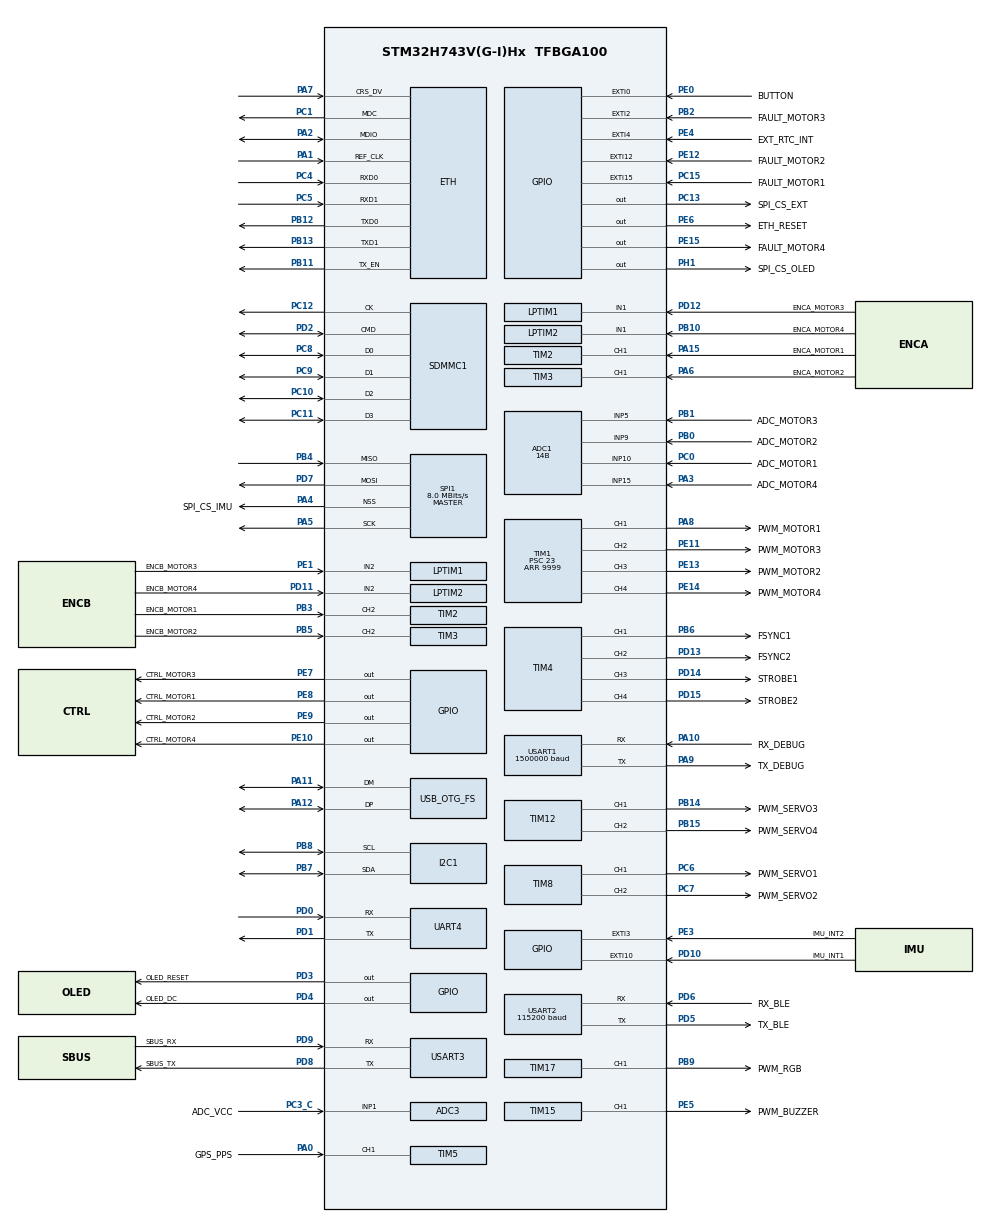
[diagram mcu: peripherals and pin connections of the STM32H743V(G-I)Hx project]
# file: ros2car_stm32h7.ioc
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ADC1.Channel-0\#ChannelRegularConversion=ADC_CHANNEL_10
ADC1.Channel-1\#ChannelRegularConversion=ADC_CHANNEL_9
ADC1.Channel-2\#ChannelRegularConversion=ADC_CHANNEL_5
ADC1.Channel-3\#ChannelRegularConversion=ADC_CHANNEL_15
ADC1.ClockPrescaler=ADC_CLOCK_ASYNC_DIV1
ADC1.ClockPrescalerADC3=ADC_CLOCK_ASYNC_DIV1
ADC1.ContinuousConvMode=ENABLE
ADC1.ConversionDataManagement=ADC_CONVERSIONDATA_DMA_CIRCULAR
ADC1.EOCSelection=ADC_EOC_SEQ_CONV
ADC1.ExternalTrigConv=ADC_SOFTWARE_START
ADC1.NbrOfConversion=4
ADC1.NbrOfConversionFlag=1
ADC1.OffsetNumber-0\#ChannelRegularConversion=ADC_OFFSET_NONE
ADC1.OffsetNumber-1\#ChannelRegularConversion=ADC_OFFSET_NONE
ADC1.OffsetNumber-2\#ChannelRegularConversion=ADC_OFFSET_NONE
ADC1.OffsetNumber-3\#ChannelRegularConversion=ADC_OFFSET_NONE
ADC1.OffsetSignedSaturation-0\#ChannelRegularConversion=DISABLE
ADC1.OffsetSignedSaturation-1\#ChannelRegularConversion=DISABLE
ADC1.OffsetSignedSaturation-2\#ChannelRegularConversion=DISABLE
ADC1.OffsetSignedSaturation-3\#ChannelRegularConversion=DISABLE
ADC1.Overrun=ADC_OVR_DATA_OVERWRITTEN
ADC1.OversamplingMode=ENABLE
ADC1.Rank-0\#ChannelRegularConversion=1
ADC1.Rank-1\#ChannelRegularConversion=2
ADC1.Rank-2\#ChannelRegularConversion=3
ADC1.Rank-3\#ChannelRegularConversion=4
ADC1.Ratio=256
ADC1.Resolution=ADC_RESOLUTION_14B
ADC1.RightBitShift=ADC_RIGHTBITSHIFT_8
ADC1.SamplingTime-0\#ChannelRegularConversion=ADC_SAMPLETIME_64CYCLES_5
ADC1.SamplingTime-1\#ChannelRegularConversion=ADC_SAMPLETIME_64CYCLES_5
ADC1.SamplingTime-2\#ChannelRegularConversion=ADC_SAMPLETIME_64CYCLES_5
ADC1.SamplingTime-3\#ChannelRegularConversion=ADC_SAMPLETIME_64CYCLES_5
ADC1.master=1
ADC3.Channel-0\#ChannelRegularConversion=ADC_CHANNEL_1
ADC3.ClockPrescaler=ADC_CLOCK_ASYNC_DIV1
ADC3.ClockPrescalerADC3=ADC_CLOCK_ASYNC_DIV1
ADC3.ContinuousConvMode=ENABLE
ADC3.ConversionDataManagement=ADC_CONVERSIONDATA_DMA_CIRCULAR
ADC3.ExternalTrigConv=ADC_SOFTWARE_START
ADC3.NbrOfConversionFlag=1
ADC3.OffsetNumber-0\#ChannelRegularConversion=ADC_OFFSET_NONE
ADC3.OffsetSignedSaturation-0\#ChannelRegularConversion=DISABLE
ADC3.Overrun=ADC_OVR_DATA_OVERWRITTEN
ADC3.OversamplingMode=ENABLE
ADC3.Rank-0\#ChannelRegularConversion=1
ADC3.Ratio=1024
ADC3.RightBitShift=ADC_RIGHTBITSHIFT_10
ADC3.SamplingTime-0\#ChannelRegularConversion=ADC_SAMPLETIME_64CYCLES_5
CORTEX_M7.AccessPermission_S-Cortex_Memory_Protection_Unit_Region1_Settings_S=MPU_REGION_FULL_ACCESS
CORTEX_M7.AccessPermission_S-Cortex_Memory_Protection_Unit_Region2_Settings_S=MPU_REGION_FULL_ACCESS
CORTEX_M7.BaseAddress_S-Cortex_Memory_Protection_Unit_Region1_Settings_S=0x30020000
CORTEX_M7.BaseAddress_S-Cortex_Memory_Protection_Unit_Region2_Settings_S=0x30000000
CORTEX_M7.CPU_DCache=Enabled
CORTEX_M7.CPU_ICache=Enabled
CORTEX_M7.DisableExec_S-Cortex_Memory_Protection_Unit_Region2_Settings_S=MPU_INSTRUCTION_ACCESS_DISABLE
CORTEX_M7.Enable_S-Cortex_Memory_Protection_Unit_Region1_Settings_S=MPU_REGION_ENABLE
CORTEX_M7.Enable_S-Cortex_Memory_Protection_Unit_Region2_Settings_S=MPU_REGION_ENABLE
CORTEX_M7.IsBufferable_S-Cortex_Memory_Protection_Unit_Region1_Settings_S=MPU_ACCESS_BUFFERABLE
CORTEX_M7.Size_S-Cortex_Memory_Protection_Unit_Region1_Settings_S=MPU_REGION_SIZE_512B
CORTEX_M7.Size_S-Cortex_Memory_Protection_Unit_Region2_Settings_S=MPU_REGION_SIZE_128KB
CORTEX_M7.TypeExtField_S-Cortex_Memory_Protection_Unit_Region2_Settings_S=MPU_TEX_LEVEL1
CORTEX_M7.default_mode_Activation=1
Dma.ADC1.10.Direction=DMA_PERIPH_TO_MEMORY
Dma.ADC1.10.EventEnable=DISABLE
Dma.ADC1.10.FIFOMode=DMA_FIFOMODE_DISABLE
Dma.ADC1.10.Instance=DMA2_Stream2
Dma.ADC1.10.MemDataAlignment=DMA_MDATAALIGN_HALFWORD
Dma.ADC1.10.MemInc=DMA_MINC_ENABLE
Dma.ADC1.10.Mode=DMA_CIRCULAR
Dma.ADC1.10.PeriphDataAlignment=DMA_PDATAALIGN_HALFWORD
Dma.ADC1.10.PeriphInc=DMA_PINC_DISABLE
Dma.ADC1.10.Polarity=HAL_DMAMUX_REQ_GEN_RISING
Dma.ADC1.10.Priority=DMA_PRIORITY_LOW
Dma.ADC1.10.RequestNumber=1
Dma.ADC1.10.SignalID=NONE
Dma.ADC1.10.SyncEnable=DISABLE
Dma.ADC1.10.SyncPolarity=HAL_DMAMUX_SYNC_NO_EVENT
Dma.ADC1.10.SyncRequestNumber=1
Dma.ADC1.10.SyncSignalID=NONE
Dma.ADC3.11.Direction=DMA_PERIPH_TO_MEMORY
Dma.ADC3.11.EventEnable=DISABLE
Dma.ADC3.11.FIFOMode=DMA_FIFOMODE_ENABLE
Dma.ADC3.11.FIFOThreshold=DMA_FIFO_THRESHOLD_FULL
Dma.ADC3.11.Instance=DMA2_Stream3
Dma.ADC3.11.MemBurst=DMA_MBURST_SINGLE
Dma.ADC3.11.MemDataAlignment=DMA_MDATAALIGN_HALFWORD
Dma.ADC3.11.MemInc=DMA_MINC_ENABLE
Dma.ADC3.11.Mode=DMA_CIRCULAR
Dma.ADC3.11.PeriphBurst=DMA_PBURST_SINGLE
Dma.ADC3.11.PeriphDataAlignment=DMA_PDATAALIGN_HALFWORD
Dma.ADC3.11.PeriphInc=DMA_PINC_DISABLE
Dma.ADC3.11.Polarity=HAL_DMAMUX_REQ_GEN_RISING
Dma.ADC3.11.Priority=DMA_PRIORITY_LOW
Dma.ADC3.11.RequestNumber=1
Dma.ADC3.11.SignalID=NONE
Dma.ADC3.11.SyncEnable=DISABLE
Dma.ADC3.11.SyncPolarity=HAL_DMAMUX_SYNC_NO_EVENT
Dma.ADC3.11.SyncRequestNumber=1
Dma.ADC3.11.SyncSignalID=NONE
Dma.Request0=USART1_RX
Dma.Request1=USART1_TX
Dma.Request10=ADC1
Dma.Request11=ADC3
Dma.Request12=TIM17_CH1
Dma.Request2=USART2_RX
Dma.Request3=USART2_TX
Dma.Request4=USART3_RX
Dma.Request5=USART3_TX
Dma.Request6=UART4_RX
Dma.Request7=UART4_TX
Dma.Request8=SPI1_RX
Dma.Request9=SPI1_TX
Dma.SPI1_RX.8.Direction=DMA_PERIPH_TO_MEMORY
Dma.SPI1_RX.8.EventEnable=DISABLE
Dma.SPI1_RX.8.FIFOMode=DMA_FIFOMODE_DISABLE
Dma.SPI1_RX.8.Instance=DMA2_Stream0
Dma.SPI1_RX.8.MemDataAlignment=DMA_MDATAALIGN_BYTE
Dma.SPI1_RX.8.MemInc=DMA_MINC_ENABLE
Dma.SPI1_RX.8.Mode=DMA_NORMAL
Dma.SPI1_RX.8.PeriphDataAlignment=DMA_PDATAALIGN_BYTE
Dma.SPI1_RX.8.PeriphInc=DMA_PINC_DISABLE
Dma.SPI1_RX.8.Polarity=HAL_DMAMUX_REQ_GEN_RISING
Dma.SPI1_RX.8.Priority=DMA_PRIORITY_LOW
Dma.SPI1_RX.8.RequestNumber=1
Dma.SPI1_RX.8.SignalID=NONE
Dma.SPI1_RX.8.SyncEnable=DISABLE
Dma.SPI1_RX.8.SyncPolarity=HAL_DMAMUX_SYNC_NO_EVENT
Dma.SPI1_RX.8.SyncRequestNumber=1
Dma.SPI1_RX.8.SyncSignalID=NONE
Dma.SPI1_TX.9.Direction=DMA_MEMORY_TO_PERIPH
Dma.SPI1_TX.9.EventEnable=DISABLE
Dma.SPI1_TX.9.FIFOMode=DMA_FIFOMODE_DISABLE
Dma.SPI1_TX.9.Instance=DMA2_Stream1
Dma.SPI1_TX.9.MemDataAlignment=DMA_MDATAALIGN_BYTE
Dma.SPI1_TX.9.MemInc=DMA_MINC_ENABLE
Dma.SPI1_TX.9.Mode=DMA_NORMAL
Dma.SPI1_TX.9.PeriphDataAlignment=DMA_PDATAALIGN_BYTE
Dma.SPI1_TX.9.PeriphInc=DMA_PINC_DISABLE
Dma.SPI1_TX.9.Polarity=HAL_DMAMUX_REQ_GEN_RISING
Dma.SPI1_TX.9.Priority=DMA_PRIORITY_LOW
Dma.SPI1_TX.9.RequestNumber=1
Dma.SPI1_TX.9.SignalID=NONE
Dma.SPI1_TX.9.SyncEnable=DISABLE
Dma.SPI1_TX.9.SyncPolarity=HAL_DMAMUX_SYNC_NO_EVENT
Dma.SPI1_TX.9.SyncRequestNumber=1
Dma.SPI1_TX.9.SyncSignalID=NONE
Dma.TIM17_CH1.12.Direction=DMA_MEMORY_TO_PERIPH
Dma.TIM17_CH1.12.EventEnable=DISABLE
Dma.TIM17_CH1.12.FIFOMode=DMA_FIFOMODE_DISABLE
Dma.TIM17_CH1.12.Instance=DMA2_Stream4
Dma.TIM17_CH1.12.MemDataAlignment=DMA_MDATAALIGN_HALFWORD
Dma.TIM17_CH1.12.MemInc=DMA_MINC_ENABLE
Dma.TIM17_CH1.12.Mode=DMA_NORMAL
Dma.TIM17_CH1.12.PeriphDataAlignment=DMA_PDATAALIGN_HALFWORD
Dma.TIM17_CH1.12.PeriphInc=DMA_PINC_DISABLE
Dma.TIM17_CH1.12.Polarity=HAL_DMAMUX_REQ_GEN_RISING
Dma.TIM17_CH1.12.Priority=DMA_PRIORITY_LOW
Dma.TIM17_CH1.12.RequestNumber=1
Dma.TIM17_CH1.12.SignalID=NONE
Dma.TIM17_CH1.12.SyncEnable=DISABLE
Dma.TIM17_CH1.12.SyncPolarity=HAL_DMAMUX_SYNC_NO_EVENT
Dma.TIM17_CH1.12.SyncRequestNumber=1
Dma.TIM17_CH1.12.SyncSignalID=NONE
Dma.UART4_RX.6.Direction=DMA_PERIPH_TO_MEMORY
Dma.UART4_RX.6.EventEnable=DISABLE
Dma.UART4_RX.6.FIFOMode=DMA_FIFOMODE_ENABLE
Dma.UART4_RX.6.FIFOThreshold=DMA_FIFO_THRESHOLD_FULL
Dma.UART4_RX.6.Instance=DMA1_Stream6
Dma.UART4_RX.6.MemBurst=DMA_MBURST_SINGLE
Dma.UART4_RX.6.MemDataAlignment=DMA_MDATAALIGN_BYTE
Dma.UART4_RX.6.MemInc=DMA_MINC_ENABLE
Dma.UART4_RX.6.Mode=DMA_NORMAL
Dma.UART4_RX.6.PeriphBurst=DMA_PBURST_SINGLE
Dma.UART4_RX.6.PeriphDataAlignment=DMA_PDATAALIGN_BYTE
Dma.UART4_RX.6.PeriphInc=DMA_PINC_DISABLE
Dma.UART4_RX.6.Polarity=HAL_DMAMUX_REQ_GEN_RISING
Dma.UART4_RX.6.Priority=DMA_PRIORITY_LOW
Dma.UART4_RX.6.RequestNumber=1
Dma.UART4_RX.6.SignalID=NONE
Dma.UART4_RX.6.SyncEnable=DISABLE
Dma.UART4_RX.6.SyncPolarity=HAL_DMAMUX_SYNC_NO_EVENT
Dma.UART4_RX.6.SyncRequestNumber=1
Dma.UART4_RX.6.SyncSignalID=NONE
Dma.UART4_TX.7.Direction=DMA_MEMORY_TO_PERIPH
Dma.UART4_TX.7.EventEnable=DISABLE
Dma.UART4_TX.7.FIFOMode=DMA_FIFOMODE_ENABLE
Dma.UART4_TX.7.FIFOThreshold=DMA_FIFO_THRESHOLD_FULL
Dma.UART4_TX.7.Instance=DMA1_Stream7
Dma.UART4_TX.7.MemBurst=DMA_MBURST_SINGLE
Dma.UART4_TX.7.MemDataAlignment=DMA_MDATAALIGN_BYTE
Dma.UART4_TX.7.MemInc=DMA_MINC_ENABLE
Dma.UART4_TX.7.Mode=DMA_NORMAL
Dma.UART4_TX.7.PeriphBurst=DMA_PBURST_SINGLE
Dma.UART4_TX.7.PeriphDataAlignment=DMA_PDATAALIGN_BYTE
Dma.UART4_TX.7.PeriphInc=DMA_PINC_DISABLE
Dma.UART4_TX.7.Polarity=HAL_DMAMUX_REQ_GEN_RISING
Dma.UART4_TX.7.Priority=DMA_PRIORITY_LOW
Dma.UART4_TX.7.RequestNumber=1
Dma.UART4_TX.7.SignalID=NONE
Dma.UART4_TX.7.SyncEnable=DISABLE
Dma.UART4_TX.7.SyncPolarity=HAL_DMAMUX_SYNC_NO_EVENT
Dma.UART4_TX.7.SyncRequestNumber=1
Dma.UART4_TX.7.SyncSignalID=NONE
Dma.USART1_RX.0.Direction=DMA_PERIPH_TO_MEMORY
Dma.USART1_RX.0.EventEnable=DISABLE
Dma.USART1_RX.0.FIFOMode=DMA_FIFOMODE_ENABLE
Dma.USART1_RX.0.FIFOThreshold=DMA_FIFO_THRESHOLD_FULL
Dma.USART1_RX.0.Instance=DMA1_Stream0
Dma.USART1_RX.0.MemBurst=DMA_MBURST_SINGLE
Dma.USART1_RX.0.MemDataAlignment=DMA_MDATAALIGN_BYTE
Dma.USART1_RX.0.MemInc=DMA_MINC_ENABLE
Dma.USART1_RX.0.Mode=DMA_NORMAL
Dma.USART1_RX.0.PeriphBurst=DMA_PBURST_SINGLE
Dma.USART1_RX.0.PeriphDataAlignment=DMA_PDATAALIGN_BYTE
Dma.USART1_RX.0.PeriphInc=DMA_PINC_DISABLE
Dma.USART1_RX.0.Polarity=HAL_DMAMUX_REQ_GEN_RISING
Dma.USART1_RX.0.Priority=DMA_PRIORITY_LOW
Dma.USART1_RX.0.RequestNumber=1
Dma.USART1_RX.0.SignalID=NONE
Dma.USART1_RX.0.SyncEnable=DISABLE
Dma.USART1_RX.0.SyncPolarity=HAL_DMAMUX_SYNC_NO_EVENT
Dma.USART1_RX.0.SyncRequestNumber=1
Dma.USART1_RX.0.SyncSignalID=NONE
Dma.USART1_TX.1.Direction=DMA_MEMORY_TO_PERIPH
Dma.USART1_TX.1.EventEnable=DISABLE
Dma.USART1_TX.1.FIFOMode=DMA_FIFOMODE_ENABLE
Dma.USART1_TX.1.FIFOThreshold=DMA_FIFO_THRESHOLD_FULL
Dma.USART1_TX.1.Instance=DMA1_Stream1
Dma.USART1_TX.1.MemBurst=DMA_MBURST_SINGLE
Dma.USART1_TX.1.MemDataAlignment=DMA_MDATAALIGN_BYTE
Dma.USART1_TX.1.MemInc=DMA_MINC_ENABLE
Dma.USART1_TX.1.Mode=DMA_NORMAL
Dma.USART1_TX.1.PeriphBurst=DMA_PBURST_SINGLE
Dma.USART1_TX.1.PeriphDataAlignment=DMA_PDATAALIGN_BYTE
Dma.USART1_TX.1.PeriphInc=DMA_PINC_DISABLE
Dma.USART1_TX.1.Polarity=HAL_DMAMUX_REQ_GEN_RISING
Dma.USART1_TX.1.Priority=DMA_PRIORITY_LOW
Dma.USART1_TX.1.RequestNumber=1
Dma.USART1_TX.1.SignalID=NONE
Dma.USART1_TX.1.SyncEnable=DISABLE
Dma.USART1_TX.1.SyncPolarity=HAL_DMAMUX_SYNC_NO_EVENT
Dma.USART1_TX.1.SyncRequestNumber=1
Dma.USART1_TX.1.SyncSignalID=NONE
Dma.USART2_RX.2.Direction=DMA_PERIPH_TO_MEMORY
Dma.USART2_RX.2.EventEnable=DISABLE
Dma.USART2_RX.2.FIFOMode=DMA_FIFOMODE_ENABLE
Dma.USART2_RX.2.FIFOThreshold=DMA_FIFO_THRESHOLD_FULL
Dma.USART2_RX.2.Instance=DMA1_Stream2
Dma.USART2_RX.2.MemBurst=DMA_MBURST_SINGLE
Dma.USART2_RX.2.MemDataAlignment=DMA_MDATAALIGN_BYTE
Dma.USART2_RX.2.MemInc=DMA_MINC_ENABLE
Dma.USART2_RX.2.Mode=DMA_NORMAL
Dma.USART2_RX.2.PeriphBurst=DMA_PBURST_SINGLE
Dma.USART2_RX.2.PeriphDataAlignment=DMA_PDATAALIGN_BYTE
Dma.USART2_RX.2.PeriphInc=DMA_PINC_DISABLE
Dma.USART2_RX.2.Polarity=HAL_DMAMUX_REQ_GEN_RISING
Dma.USART2_RX.2.Priority=DMA_PRIORITY_LOW
Dma.USART2_RX.2.RequestNumber=1
Dma.USART2_RX.2.SignalID=NONE
Dma.USART2_RX.2.SyncEnable=DISABLE
Dma.USART2_RX.2.SyncPolarity=HAL_DMAMUX_SYNC_NO_EVENT
Dma.USART2_RX.2.SyncRequestNumber=1
Dma.USART2_RX.2.SyncSignalID=NONE
Dma.USART2_TX.3.Direction=DMA_MEMORY_TO_PERIPH
Dma.USART2_TX.3.EventEnable=DISABLE
Dma.USART2_TX.3.FIFOMode=DMA_FIFOMODE_ENABLE
Dma.USART2_TX.3.FIFOThreshold=DMA_FIFO_THRESHOLD_FULL
Dma.USART2_TX.3.Instance=DMA1_Stream3
Dma.USART2_TX.3.MemBurst=DMA_MBURST_SINGLE
Dma.USART2_TX.3.MemDataAlignment=DMA_MDATAALIGN_BYTE
Dma.USART2_TX.3.MemInc=DMA_MINC_ENABLE
Dma.USART2_TX.3.Mode=DMA_NORMAL
Dma.USART2_TX.3.PeriphBurst=DMA_PBURST_SINGLE
Dma.USART2_TX.3.PeriphDataAlignment=DMA_PDATAALIGN_BYTE
Dma.USART2_TX.3.PeriphInc=DMA_PINC_DISABLE
Dma.USART2_TX.3.Polarity=HAL_DMAMUX_REQ_GEN_RISING
Dma.USART2_TX.3.Priority=DMA_PRIORITY_LOW
Dma.USART2_TX.3.RequestNumber=1
Dma.USART2_TX.3.SignalID=NONE
Dma.USART2_TX.3.SyncEnable=DISABLE
Dma.USART2_TX.3.SyncPolarity=HAL_DMAMUX_SYNC_NO_EVENT
Dma.USART2_TX.3.SyncRequestNumber=1
Dma.USART2_TX.3.SyncSignalID=NONE
Dma.USART3_RX.4.Direction=DMA_PERIPH_TO_MEMORY
Dma.USART3_RX.4.EventEnable=DISABLE
Dma.USART3_RX.4.FIFOMode=DMA_FIFOMODE_DISABLE
Dma.USART3_RX.4.Instance=DMA1_Stream4
Dma.USART3_RX.4.MemDataAlignment=DMA_MDATAALIGN_BYTE
Dma.USART3_RX.4.MemInc=DMA_MINC_ENABLE
Dma.USART3_RX.4.Mode=DMA_NORMAL
Dma.USART3_RX.4.PeriphDataAlignment=DMA_PDATAALIGN_BYTE
Dma.USART3_RX.4.PeriphInc=DMA_PINC_DISABLE
Dma.USART3_RX.4.Polarity=HAL_DMAMUX_REQ_GEN_RISING
Dma.USART3_RX.4.Priority=DMA_PRIORITY_LOW
Dma.USART3_RX.4.RequestNumber=1
Dma.USART3_RX.4.SignalID=NONE
Dma.USART3_RX.4.SyncEnable=DISABLE
Dma.USART3_RX.4.SyncPolarity=HAL_DMAMUX_SYNC_NO_EVENT
Dma.USART3_RX.4.SyncRequestNumber=1
Dma.USART3_RX.4.SyncSignalID=NONE
Dma.USART3_TX.5.Direction=DMA_MEMORY_TO_PERIPH
Dma.USART3_TX.5.EventEnable=DISABLE
Dma.USART3_TX.5.FIFOMode=DMA_FIFOMODE_DISABLE
Dma.USART3_TX.5.Instance=DMA1_Stream5
Dma.USART3_TX.5.MemDataAlignment=DMA_MDATAALIGN_BYTE
Dma.USART3_TX.5.MemInc=DMA_MINC_ENABLE
Dma.USART3_TX.5.Mode=DMA_NORMAL
Dma.USART3_TX.5.PeriphDataAlignment=DMA_PDATAALIGN_BYTE
Dma.USART3_TX.5.PeriphInc=DMA_PINC_DISABLE
Dma.USART3_TX.5.Polarity=HAL_DMAMUX_REQ_GEN_RISING
Dma.USART3_TX.5.Priority=DMA_PRIORITY_LOW
Dma.USART3_TX.5.RequestNumber=1
Dma.USART3_TX.5.SignalID=NONE
Dma.USART3_TX.5.SyncEnable=DISABLE
Dma.USART3_TX.5.SyncPolarity=HAL_DMAMUX_SYNC_NO_EVENT
Dma.USART3_TX.5.SyncRequestNumber=1
Dma.USART3_TX.5.SyncSignalID=NONE
ETH.ETH_RX_DESC_CNT=8
ETH.ETH_TX_DESC_CNT=8
ETH.MediaInterface=HAL_ETH_RMII_MODE
ETH.RxBufferAddress=0x30020200
ETH.RxDescAddress=0x30020000
ETH.TxDescAddress=0x30020100
FATFS._CODE_PAGE=1
FATFS._USE_MUTEX=1
FREERTOS.INCLUDE_vTaskDelayUntil=1
FREERTOS.Tasks01=startup_task,0,1024,startup,Default,NULL,Dynamic,NULL,NULL;cmd_process_task,0,256,cmd_process,Default,NULL,Dynamic,NULL,NULL
FREERTOS.configCHECK_FOR_STACK_OVERFLOW=2
FREERTOS.configENABLE_FPU=1
FREERTOS.configGENERATE_RUN_TIME_STATS=1
FREERTOS.configMAX_TASK_NAME_LEN=32
FREERTOS.configTOTAL_HEAP_SIZE=0x20000
FREERTOS.configUSE_TIMERS=1
FREERTOS.configUSE_TRACE_FACILITY=1
I2C1.Timing=0x307075B1
IWDG1.Prescaler=IWDG_PRESCALER_64
LWIP.API_LIB_DEBUG=LWIP_DBG_ON
LWIP.API_MSG_DEBUG=LWIP_DBG_ON
LWIP.BSP.number=1
LWIP.DEFAULT_TCP_RECVMBOX_SIZE=6
LWIP.DEFAULT_THREAD_PRIO=4
LWIP.DEFAULT_THREAD_STACKSIZE=2048
LWIP.ETHARP_DEBUG=LWIP_DBG_ON
LWIP.ETH_RX_BUFFER_CNT=48
LWIP.GATEWAY_ADDRESS=192.168.123.001
LWIP.ICMP_DEBUG=LWIP_DBG_ON
LWIP.IGMP_DEBUG=LWIP_DBG_ON
LWIP.INET_DEBUG=LWIP_DBG_ON
LWIP.IP_ADDRESS=192.168.123.004
LWIP.IP_DEBUG=LWIP_DBG_ON
LWIP.IP_FRAG=1
LWIP.IP_REASS_DEBUG=LWIP_DBG_ON
LWIP.LWIP_DBG_MIN_LEVEL=LWIP_DBG_LEVEL_WARNING
LWIP.LWIP_DHCP=1
LWIP.LWIP_IGMP=1
LWIP.LWIP_MULTICAST_PING=0
LWIP.LWIP_MULTICAST_TX_OPTIONS=1
LWIP.LWIP_NETCONN=0
LWIP.LWIP_RAM_HEAP_POINTER=0x30000000
LWIP.LWIP_TCP=0
LWIP.LWIP_UDP=1
LWIP.MEMP_DEBUG=LWIP_DBG_ON
LWIP.MEMP_NUM_PBUF=64
LWIP.MEMP_NUM_TCPIP_MSG_API=64
LWIP.MEMP_NUM_TCPIP_MSG_INPKT=1024
LWIP.MEMP_NUM_TCP_SEG=32
LWIP.MEM_DEBUG=LWIP_DBG_ON
LWIP.MEM_SIZE=0x20000
LWIP.NETIF_DEBUG=LWIP_DBG_ON
LWIP.NETMASK_ADDRESS=255.255.255.000
LWIP.PBUF_DEBUG=LWIP_DBG_ON
LWIP.PBUF_POOL_BUFSIZE=768
LWIP.PBUF_POOL_SIZE=128
LWIP.RAW_DEBUG=LWIP_DBG_ON
LWIP.SLIPIF_THREAD_STACKSIZE=1024
LWIP.SYS_DEBUG=LWIP_DBG_ON
LWIP.TCPIP_DEBUG=LWIP_DBG_ON
LWIP.TCPIP_THREAD_PRIO=4
LWIP.TCPIP_THREAD_STACKSIZE=2048
LWIP.TCP_CWND_DEBUG=LWIP_DBG_ON
LWIP.TCP_DEBUG=LWIP_DBG_ON
LWIP.TCP_FR_DEBUG=LWIP_DBG_ON
LWIP.TCP_INPUT_DEBUG=LWIP_DBG_ON
LWIP.TCP_MSS=1024
LWIP.TCP_OUTPUT_DEBUG=LWIP_DBG_ON
LWIP.TCP_QLEN_DEBUG=LWIP_DBG_ON
LWIP.TCP_RST_DEBUG=LWIP_DBG_ON
LWIP.TCP_RTO_DEBUG=LWIP_DBG_ON
LWIP.TCP_SND_QUEUELEN=16
LWIP.TCP_WND_DEBUG=LWIP_DBG_ON
LWIP.TIMERS_DEBUG=LWIP_DBG_ON
LWIP.UDP_DEBUG=LWIP_DBG_ON
LWIP.Version=v2.1.2_Cube
LWIP0.BSP.STBoard=false
LWIP0.BSP.api=BSP_COMPONENT_DRIVER
LWIP0.BSP.component=LAN8742
LWIP0.BSP.instance=LAN8742
LWIP0.BSP.name=Driver_PHY
LWIP0.BSP.semaphore=S_LAN8742
LWIP0.BSP.solution=LAN8742
Mcu.Family=STM32H7
Mcu.Name=STM32H743V(G-I)Hx
Mcu.Package=TFBGA100
Mcu.UserConstants=GPS_PPS_TIM,$$_TIM5_IP_HANDLE_$$;MOTOR1_ENC_TIM,TIM2;BUZZER_TIM,$$_TIM15_IP_HANDLE_$$;MOTOR_PWM_TIM,TIM1;ENC_TIME_TIM,$$_TIM7_IP_HANDLE_$$;CAM_SYNC_TIM,$$_TIM4_IP_HANDLE_$$;SERVO12_TIM,$$_TIM8_IP_HANDLE_$$;MOTOR2_ENC_TIM,TIM3;MOTOR3_ENC_TIM,$$_LPTIM1_IP_HANDLE_$$;SERVO34_TIM,$$_TIM12_IP_HANDLE_$$;MOTOR4_ENC_TIM,$$_LPTIM2_IP_HANDLE_$$;RGB_TIM,$$_TIM17_IP_HANDLE_$$
NVIC.DMA1_Stream0_IRQn=true\:5\:0\:false\:false\:true\:true\:false\:true\:true
NVIC.DMA1_Stream1_IRQn=true\:5\:0\:false\:false\:true\:true\:false\:true\:true
NVIC.DMA1_Stream2_IRQn=true\:5\:0\:false\:false\:true\:true\:false\:true\:true
NVIC.DMA1_Stream3_IRQn=true\:5\:0\:false\:false\:true\:true\:false\:true\:true
NVIC.DMA1_Stream4_IRQn=true\:5\:0\:false\:false\:true\:true\:false\:true\:true
NVIC.DMA1_Stream5_IRQn=true\:5\:0\:false\:false\:true\:true\:false\:true\:true
NVIC.DMA1_Stream6_IRQn=true\:5\:0\:false\:false\:true\:true\:false\:true\:true
NVIC.DMA1_Stream7_IRQn=true\:5\:0\:false\:false\:true\:true\:false\:true\:true
NVIC.DMA2_Stream0_IRQn=true\:5\:0\:false\:false\:true\:true\:false\:true\:true
NVIC.DMA2_Stream1_IRQn=true\:5\:0\:false\:false\:true\:true\:false\:true\:true
NVIC.DMA2_Stream2_IRQn=true\:5\:0\:false\:false\:true\:true\:true\:true\:true
NVIC.DMA2_Stream4_IRQn=true\:5\:0\:false\:false\:true\:true\:false\:true\:true
NVIC.EXTI0_IRQn=true\:5\:0\:false\:false\:true\:true\:true\:true\:true
NVIC.EXTI15_10_IRQn=true\:5\:0\:false\:false\:true\:true\:true\:true\:true
NVIC.EXTI2_IRQn=true\:5\:0\:false\:false\:true\:true\:true\:true\:true
NVIC.EXTI3_IRQn=true\:5\:0\:false\:false\:true\:true\:true\:true\:true
NVIC.EXTI4_IRQn=true\:5\:0\:false\:false\:true\:true\:true\:true\:true
NVIC.OTG_FS_EP1_IN_IRQn=true\:5\:0\:false\:false\:true\:true\:true\:true\:true
NVIC.OTG_FS_EP1_OUT_IRQn=true\:5\:0\:false\:false\:true\:true\:true\:true\:true
NVIC.OTG_FS_IRQn=true\:5\:0\:false\:false\:true\:true\:true\:true\:true
NVIC.PVD_AVD_IRQn=true\:5\:0\:false\:false\:true\:true\:true\:true\:true
NVIC.PriorityGroup=NVIC_PRIORITYGROUP_4
NVIC.SDMMC1_IRQn=true\:5\:0\:false\:false\:true\:true\:true\:true\:true
NVIC.SPI1_IRQn=true\:5\:0\:false\:false\:true\:true\:false\:true\:true
NVIC.TIM6_DAC_IRQn=true\:15\:0\:false\:false\:true\:false\:true\:true\:true
NVIC.TIM7_IRQn=true\:5\:0\:false\:false\:true\:true\:true\:true\:true
NVIC.TimeBase=TIM6_DAC_IRQn
NVIC.TimeBaseIP=TIM6
NVIC.UART4_IRQn=true\:5\:0\:false\:false\:true\:true\:false\:true\:true
NVIC.USART1_IRQn=true\:5\:0\:false\:false\:true\:true\:false\:true\:true
NVIC.USART2_IRQn=true\:5\:0\:false\:false\:true\:true\:false\:true\:true
NVIC.USART3_IRQn=true\:5\:0\:false\:false\:true\:true\:false\:true\:true
PA0.GPIO_Label=GPS_PPS
PA0.GPIO_Speed=GPIO_SPEED_FREQ_VERY_HIGH
PA0.PinAttribute=Free
PA0.Signal=S_TIM5_CH1
PA1.GPIO_Speed=GPIO_SPEED_FREQ_VERY_HIGH
PA1.Mode=RMII
PA1.Signal=ETH_REF_CLK
PA10.GPIO_Label=RX_DEBUG
PA10.GPIO_Speed=GPIO_SPEED_FREQ_VERY_HIGH
PA10.Mode=Asynchronous
PA10.PinAttribute=Free
PA10.Signal=USART1_RX
PA11.GPIO_Speed=GPIO_SPEED_FREQ_VERY_HIGH
PA11.Mode=Device_Only
PA11.PinAttribute=Free
PA11.Signal=USB_OTG_FS_DM
PA12.GPIO_Speed=GPIO_SPEED_FREQ_VERY_HIGH
PA12.Mode=Device_Only
PA12.Signal=USB_OTG_FS_DP
PA13\ (JTMS/SWDIO).Mode=Serial_Wire
PA13\ (JTMS/SWDIO).Signal=DEBUG_JTMS-SWDIO
PA14\ (JTCK/SWCLK).Mode=Serial_Wire
PA14\ (JTCK/SWCLK).Signal=DEBUG_JTCK-SWCLK
PA15\ (JTDI).GPIO_Label=ENCA_MOTOR1
PA15\ (JTDI).GPIO_Speed=GPIO_SPEED_FREQ_VERY_HIGH
PA15\ (JTDI).Signal=S_TIM2_CH1_ETR
PA2.GPIO_Speed=GPIO_SPEED_FREQ_VERY_HIGH
PA2.Mode=RMII
PA2.Signal=ETH_MDIO
PA3.GPIO_Label=ADC_MOTOR4
PA3.Signal=ADCx_INP15
PA4.GPIO_Label=SPI_CS_IMU
PA4.GPIO_Speed=GPIO_SPEED_FREQ_VERY_HIGH
PA4.Mode=NSS_Signal_Hard_Output
PA4.PinAttribute=Free
PA4.Signal=SPI1_NSS
PA5.GPIO_Speed=GPIO_SPEED_FREQ_VERY_HIGH
PA5.Mode=Full_Duplex_Master
PA5.Signal=SPI1_SCK
PA6.GPIO_Label=ENCA_MOTOR2
PA6.GPIO_Speed=GPIO_SPEED_FREQ_VERY_HIGH
PA6.Signal=S_TIM3_CH1
PA7.GPIO_Speed=GPIO_SPEED_FREQ_VERY_HIGH
PA7.Mode=RMII
PA7.Signal=ETH_CRS_DV
PA8.GPIO_Label=PWM_MOTOR1
PA8.GPIO_Speed=GPIO_SPEED_FREQ_VERY_HIGH
PA8.PinAttribute=Free
PA8.Signal=S_TIM1_CH1
PA9.GPIO_Label=TX_DEBUG
PA9.GPIO_Speed=GPIO_SPEED_FREQ_VERY_HIGH
PA9.Mode=Asynchronous
PA9.PinAttribute=Free
PA9.Signal=USART1_TX
PB0.GPIO_Label=ADC_MOTOR2
PB0.Signal=ADCx_INP9
PB1.GPIO_Label=ADC_MOTOR3
PB1.Signal=ADCx_INP5
PB10.GPIO_Label=ENCA_MOTOR4
PB10.GPIO_Speed=GPIO_SPEED_FREQ_VERY_HIGH
PB10.Mode=Encoder_mode_occur1
PB10.Signal=LPTIM2_IN1
PB11.GPIO_Speed=GPIO_SPEED_FREQ_VERY_HIGH
PB11.Mode=RMII
PB11.Signal=ETH_TX_EN
PB12.GPIO_Speed=GPIO_SPEED_FREQ_VERY_HIGH
PB12.Mode=RMII
PB12.Signal=ETH_TXD0
PB13.GPIO_Speed=GPIO_SPEED_FREQ_VERY_HIGH
PB13.Mode=RMII
PB13.Signal=ETH_TXD1
PB14.GPIO_Label=PWM_SERVO3
PB14.GPIO_Speed=GPIO_SPEED_FREQ_VERY_HIGH
PB14.Signal=S_TIM12_CH1
PB15.GPIO_Label=PWM_SERVO4
PB15.GPIO_Speed=GPIO_SPEED_FREQ_VERY_HIGH
PB15.Signal=S_TIM12_CH2
PB2.GPIO_Label=FAULT_MOTOR3
PB2.PinAttribute=Free
PB2.Signal=GPXTI2
PB3\ (JTDO/TRACESWO).GPIO_Label=ENCB_MOTOR1
PB3\ (JTDO/TRACESWO).GPIO_Speed=GPIO_SPEED_FREQ_VERY_HIGH
PB3\ (JTDO/TRACESWO).Signal=S_TIM2_CH2
PB4\ (NJTRST).GPIO_Speed=GPIO_SPEED_FREQ_VERY_HIGH
PB4\ (NJTRST).Mode=Full_Duplex_Master
PB4\ (NJTRST).Signal=SPI1_MISO
PB5.GPIO_Label=ENCB_MOTOR2
PB5.GPIO_Speed=GPIO_SPEED_FREQ_VERY_HIGH
PB5.PinAttribute=Free
PB5.Signal=S_TIM3_CH2
PB6.GPIO_FM6=SYSCFG_PMCR_I2C_PB6_FMP
PB6.GPIO_Label=FSYNC1
PB6.GPIO_Speed=GPIO_SPEED_FREQ_VERY_HIGH
PB6.Signal=S_TIM4_CH1
PB7.GPIO_Speed=GPIO_SPEED_FREQ_HIGH
PB7.Mode=I2C
PB7.Signal=I2C1_SDA
PB8.GPIO_Speed=GPIO_SPEED_FREQ_HIGH
PB8.Mode=I2C
PB8.Signal=I2C1_SCL
PB9.GPIO_FM9=SYSCFG_PMCR_I2C_PB9_FMP
PB9.GPIO_Label=PWM_RGB
PB9.GPIO_Speed=GPIO_SPEED_FREQ_VERY_HIGH
PB9.Signal=S_TIM17_CH1
PC0.GPIO_Label=ADC_MOTOR1
PC0.PinAttribute=Free
PC0.Signal=ADCx_INP10
PC1.GPIO_Speed=GPIO_SPEED_FREQ_VERY_HIGH
PC1.Mode=RMII
PC1.PinAttribute=Free
PC1.Signal=ETH_MDC
PC10.Mode=SD_4_bits_Wide_bus
PC10.Signal=SDMMC1_D2
PC11.Mode=SD_4_bits_Wide_bus
PC11.Signal=SDMMC1_D3
PC12.Mode=SD_4_bits_Wide_bus
PC12.PinAttribute=Free
PC12.Signal=SDMMC1_CK
PC13.GPIO_Label=SPI_CS_EXT
PC13.PinState=GPIO_PIN_SET
PC13.Signal=GPIO_Output
PC14-OSC32_IN\ (OSC32_IN).Mode=LSE-External-Clock-Source
PC14-OSC32_IN\ (OSC32_IN).Signal=RCC_OSC32_IN
PC15-OSC32_OUT\ (OSC32_OUT).GPIO_Label=FAULT_MOTOR1
PC15-OSC32_OUT\ (OSC32_OUT).Signal=GPXTI15
PC3_C.GPIO_Label=ADC_VCC
PC3_C.Mode=IN1-Single-Ended
PC3_C.PinAttribute=Free
PC3_C.Signal=ADC3_INP1
PC4.GPIO_Speed=GPIO_SPEED_FREQ_VERY_HIGH
PC4.Mode=RMII
PC4.PinAttribute=Free
PC4.Signal=ETH_RXD0
PC5.GPIO_Speed=GPIO_SPEED_FREQ_VERY_HIGH
PC5.Mode=RMII
PC5.Signal=ETH_RXD1
PC6.GPIO_Label=PWM_SERVO1
PC6.GPIO_Speed=GPIO_SPEED_FREQ_VERY_HIGH
PC6.PinAttribute=Free
PC6.Signal=S_TIM8_CH1
PC7.GPIO_Label=PWM_SERVO2
PC7.GPIO_Speed=GPIO_SPEED_FREQ_VERY_HIGH
PC7.PinAttribute=Free
PC7.Signal=S_TIM8_CH2
PC8.Mode=SD_4_bits_Wide_bus
PC8.PinAttribute=Free
PC8.Signal=SDMMC1_D0
PC9.Mode=SD_4_bits_Wide_bus
PC9.PinAttribute=Free
PC9.Signal=SDMMC1_D1
PD0.GPIO_FM8=SYSCFG_PMCR_I2C_PB8_FMP
PD0.GPIO_Speed=GPIO_SPEED_FREQ_VERY_HIGH
PD0.Mode=Asynchronous
PD0.PinAttribute=Free
PD0.Signal=UART4_RX
PD1.GPIO_Speed=GPIO_SPEED_FREQ_VERY_HIGH
PD1.Mode=Asynchronous
PD1.PinAttribute=Free
PD1.Signal=UART4_TX
PD10.GPIO_Label=IMU_INT1
PD10.Signal=GPXTI10
PD11.GPIO_Label=ENCB_MOTOR4
PD11.GPIO_Speed=GPIO_SPEED_FREQ_VERY_HIGH
PD11.Mode=Encoder_mode_occur1
PD11.PinAttribute=Free
PD11.Signal=LPTIM2_IN2
PD12.GPIO_Label=ENCA_MOTOR3
PD12.GPIO_Speed=GPIO_SPEED_FREQ_VERY_HIGH
PD12.Mode=Encoder_mode_occur1
PD12.Signal=LPTIM1_IN1
PD13.GPIO_Label=FSYNC2
PD13.GPIO_Speed=GPIO_SPEED_FREQ_VERY_HIGH
PD13.Signal=S_TIM4_CH2
PD14.GPIO_Label=STROBE1
PD14.GPIO_Speed=GPIO_SPEED_FREQ_VERY_HIGH
PD14.Signal=S_TIM4_CH3
PD15.GPIO_Label=STROBE2
PD15.GPIO_Speed=GPIO_SPEED_FREQ_VERY_HIGH
PD15.PinAttribute=Free
PD15.Signal=S_TIM4_CH4
PD2.Mode=SD_4_bits_Wide_bus
PD2.Signal=SDMMC1_CMD
PD3.GPIO_Label=OLED_RESET
PD3.PinAttribute=Free
PD3.PinState=GPIO_PIN_SET
PD3.Signal=GPIO_Output
PD4.GPIO_Label=OLED_DC
PD4.PinAttribute=Free
PD4.Signal=GPIO_Output
PD5.GPIO_Label=TX_BLE
PD5.GPIO_Speed=GPIO_SPEED_FREQ_VERY_HIGH
PD5.Mode=Asynchronous
PD5.Signal=USART2_TX
PD6.GPIO_Label=RX_BLE
PD6.GPIO_Speed=GPIO_SPEED_FREQ_VERY_HIGH
PD6.Mode=Asynchronous
PD6.PinAttribute=Free
PD6.Signal=USART2_RX
PD7.GPIO_Speed=GPIO_SPEED_FREQ_VERY_HIGH
PD7.Mode=Full_Duplex_Master
PD7.PinAttribute=Free
PD7.Signal=SPI1_MOSI
PD8.GPIO_Label=SBUS_TX
PD8.GPIO_Speed=GPIO_SPEED_FREQ_VERY_HIGH
PD8.Mode=Asynchronous
PD8.Signal=USART3_TX
PD9.GPIO_Label=SBUS_RX
PD9.GPIO_Speed=GPIO_SPEED_FREQ_VERY_HIGH
PD9.Mode=Asynchronous
PD9.Signal=USART3_RX
PE0.GPIO_Label=BUTTON
PE0.Signal=GPXTI0
PE1.GPIO_Label=ENCB_MOTOR3
PE1.GPIO_Speed=GPIO_SPEED_FREQ_VERY_HIGH
PE1.Mode=Encoder_mode_occur1
PE1.PinAttribute=Free
PE1.Signal=LPTIM1_IN2
PE10.GPIO_Label=CTRL_MOTOR4
PE10.PinAttribute=Free
PE10.Signal=GPIO_Output
PE11.GPIO_Label=PWM_MOTOR3
PE11.GPIO_Speed=GPIO_SPEED_FREQ_VERY_HIGH
PE11.Signal=S_TIM1_CH2
PE12.GPIO_Label=FAULT_MOTOR2
PE12.Signal=GPXTI12
PE13.GPIO_Label=PWM_MOTOR2
PE13.GPIO_Speed=GPIO_SPEED_FREQ_VERY_HIGH
PE13.Signal=S_TIM1_CH3
PE14.GPIO_Label=PWM_MOTOR4
PE14.GPIO_Speed=GPIO_SPEED_FREQ_VERY_HIGH
PE14.PinAttribute=Free
PE14.Signal=S_TIM1_CH4
PE15.GPIO_Label=FAULT_MOTOR4
PE15.Signal=GPIO_Output
PE3.GPIO_Label=IMU_INT2
PE3.Signal=GPXTI3
PE4.GPIO_Label=EXT_RTC_INT
PE4.PinAttribute=Free
PE4.Signal=GPXTI4
PE5.GPIO_Label=PWM_BUZZER
PE5.GPIO_Speed=GPIO_SPEED_FREQ_VERY_HIGH
PE5.Signal=S_TIM15_CH1
PE6.GPIO_Label=ETH_RESET
PE6.PinAttribute=Free
PE6.PinState=GPIO_PIN_SET
PE6.Signal=GPIO_Output
PE7.GPIO_Label=CTRL_MOTOR3
PE7.Signal=GPIO_Output
PE8.GPIO_Label=CTRL_MOTOR1
PE8.Signal=GPIO_Output
PE9.GPIO_Label=CTRL_MOTOR2
PE9.Signal=GPIO_Output
PH0-OSC_IN\ (PH0).Mode=HSE-External-Clock-Source
PH0-OSC_IN\ (PH0).Signal=RCC_OSC_IN
PH1-OSC_OUT\ (PH1).GPIO_Label=SPI_CS_OLED
PH1-OSC_OUT\ (PH1).PinAttribute=Free
PH1-OSC_OUT\ (PH1).PinState=GPIO_PIN_SET
PH1-OSC_OUT\ (PH1).Signal=GPIO_Output
PWR.PVDLevel=PWR_PVDLEVEL_6
ProjectManager.HeapSize=0x800
ProjectManager.StackSize=0x800
ProjectManager.TargetToolchain=CMake
RCC.ADCFreq_Value=72000000
RCC.APB1Freq_Value=120000000
RCC.APB2Freq_Value=120000000
RCC.APB3Freq_Value=120000000
RCC.APB4Freq_Value=120000000
RCC.CortexFreq_Value=480000000
RCC.D1PPRE=RCC_APB3_DIV2
RCC.D2PPRE1=RCC_APB1_DIV2
RCC.D2PPRE2=RCC_APB2_DIV2
RCC.D3PPRE=RCC_APB4_DIV2
RCC.DIVM1=3
RCC.DIVM2=3
RCC.DIVM3=3
RCC.DIVN1=72
RCC.DIVN2=27
RCC.DIVN3=27
RCC.DIVP2=5
RCC.DIVP3=5
RCC.DIVQ1=15
RCC.DIVQ2=5
RCC.DIVQ3=5
RCC.DIVR1=12
RCC.DIVR2=5
RCC.DIVR3=5
RCC.HCLKFreq_Value=240000000
RCC.HPRE=RCC_HCLK_DIV2
RCC.HRTIMCLockSelection=RCC_HRTIM1CLK_CPUCLK
RCC.HSE_VALUE=40000000
RCC.PLL1_VCO_SEL-AdvancedSettings=RCC_PLL1VCOMEDIUM
RCC.PLL2FRACN=0
RCC.PLL2_VCI_Range-AdvancedSettings=RCC_PLL2VCIRANGE_0
RCC.PLL3FRACN=0
RCC.PLL3_VCI_Range-AdvancedSettings=RCC_PLL3VCIRANGE_0
RCC.PLL3_VCO_SEL-AdvancedSettings=RCC_PLL3VCOMEDIUM
RCC.PLLFRACN=0
RCC.PLLSourceVirtual=RCC_PLLSOURCE_HSE
RCC.RCC_RTC_Clock_Source_FROM_HSE=RCC_RTCCLKSOURCE_HSE_DIV40
RCC.RTCClockSelection=RCC_RTCCLKSOURCE_HSE_DIV40
RCC.SYSCLKFreq_VALUE=480000000
RCC.SYSCLKSource=RCC_SYSCLKSOURCE_PLLCLK
RCC.USBFreq_Value=64000000
SH.ADCx_INP10.0=ADC1_INP10,IN10-Single-Ended
SH.ADCx_INP15.0=ADC1_INP15,IN15-Single-Ended
SH.ADCx_INP5.0=ADC1_INP5,IN5-Single-Ended
SH.ADCx_INP9.0=ADC1_INP9,IN9-Single-Ended
SH.S_TIM12_CH1.0=TIM12_CH1,PWM Generation1 CH1
SH.S_TIM12_CH2.0=TIM12_CH2,PWM Generation2 CH2
SH.S_TIM15_CH1.0=TIM15_CH1,PWM Generation1 CH1
SH.S_TIM17_CH1.0=TIM17_CH1,PWM Generation1 CH1
SH.S_TIM1_CH1.0=TIM1_CH1,PWM Generation1 CH1
SH.S_TIM1_CH2.0=TIM1_CH2,PWM Generation2 CH2
SH.S_TIM1_CH3.0=TIM1_CH3,PWM Generation3 CH3
SH.S_TIM1_CH4.0=TIM1_CH4,PWM Generation4 CH4
SH.S_TIM2_CH1_ETR.0=TIM2_CH1,Encoder_Interface
SH.S_TIM2_CH2.0=TIM2_CH2,Encoder_Interface
SH.S_TIM3_CH1.0=TIM3_CH1,Encoder_Interface
SH.S_TIM3_CH2.0=TIM3_CH2,Encoder_Interface
SH.S_TIM4_CH1.0=TIM4_CH1,PWM Generation1 CH1
SH.S_TIM4_CH2.0=TIM4_CH2,PWM Generation2 CH2
SH.S_TIM4_CH3.0=TIM4_CH3,PWM Generation3 CH3
SH.S_TIM4_CH4.0=TIM4_CH4,PWM Generation4 CH4
SH.S_TIM5_CH1.0=TIM5_CH1,Input_Capture1_from_TI1
SH.S_TIM8_CH1.0=TIM8_CH1,PWM Generation1 CH1
SH.S_TIM8_CH2.0=TIM8_CH2,PWM Generation2 CH2
SPI1.BaudRatePrescaler=SPI_BAUDRATEPRESCALER_8
SPI1.CLKPhase=SPI_PHASE_2EDGE
SPI1.CLKPolarity=SPI_POLARITY_HIGH
SPI1.CalculateBaudRate=8.0 MBits/s
SPI1.DataSize=SPI_DATASIZE_8BIT
SPI1.Direction=SPI_DIRECTION_2LINES
SPI1.Mode=SPI_MODE_MASTER
SPI1.VirtualNSS=VM_NSSHARD
SPI1.VirtualType=VM_MASTER
TIM1.Channel-PWM\ Generation1\ CH1=TIM_CHANNEL_1
TIM1.Channel-PWM\ Generation2\ CH2=TIM_CHANNEL_2
TIM1.Channel-PWM\ Generation3\ CH3=TIM_CHANNEL_3
TIM1.Channel-PWM\ Generation4\ CH4=TIM_CHANNEL_4
TIM1.Period=9999
TIM1.Prescaler=23
TIM12.Channel-PWM\ Generation1\ CH1=TIM_CHANNEL_1
TIM12.Channel-PWM\ Generation2\ CH2=TIM_CHANNEL_2
TIM15.AutoReloadPreload=TIM_AUTORELOAD_PRELOAD_ENABLE
TIM15.Channel-PWM\ Generation1\ CH1=TIM_CHANNEL_1
TIM15.Period=65535
TIM15.Prescaler=239
TIM17.Channel=TIM_CHANNEL_1
TIM17.Period=299
TIM2.EncoderMode=TIM_ENCODERMODE_TI12
TIM3.EncoderMode=TIM_ENCODERMODE_TI12
TIM4.Channel-PWM\ Generation1\ CH1=TIM_CHANNEL_1
TIM4.Channel-PWM\ Generation2\ CH2=TIM_CHANNEL_2
TIM4.Channel-PWM\ Generation3\ CH3=TIM_CHANNEL_3
TIM4.Channel-PWM\ Generation4\ CH4=TIM_CHANNEL_4
TIM5.Channel-Input_Capture1_from_TI1=TIM_CHANNEL_1
TIM7.AutoReloadPreload=TIM_AUTORELOAD_PRELOAD_DISABLE
TIM7.Period=65535
TIM7.Prescaler=239
TIM8.Channel-PWM\ Generation1\ CH1=TIM_CHANNEL_1
TIM8.Channel-PWM\ Generation2\ CH2=TIM_CHANNEL_2
UART4.FIFOMode=FIFOMODE_ENABLE
USART1.BaudRate=1500000
USART1.FIFOMode=FIFOMODE_ENABLE
USART1.VirtualMode-Asynchronous=VM_ASYNC
USART2.BaudRate=115200
USART2.FIFOMode=FIFOMODE_ENABLE
USART2.VirtualMode-Asynchronous=VM_ASYNC
USART3.FIFOMode=FIFOMODE_ENABLE
USART3.VirtualMode-Asynchronous=VM_ASYNC
USB_DEVICE.APP_RX_DATA_SIZE-CDC_FS=1024
USB_DEVICE.CLASS_NAME_FS=CDC
USB_DEVICE.VirtualMode-CDC_FS=Cdc
USB_DEVICE.VirtualModeFS=Cdc_FS
USB_OTG_FS.VirtualMode=Device_Only
USB_OTG_FS.dma_enable=ENABLE
USB_OTG_FS.use_dedicated_ep1=ENABLE
VP_ADC3_TempSens_Input.Mode=IN-TempSens
VP_ADC3_Vbat_Input.Mode=IN-Vbat
VP_CRC_VS_CRC.Mode=CRC_Activate
VP_FATFS_VS_SDIO.Mode=SDIO
VP_FREERTOS_VS_CMSIS_V1.Mode=CMSIS_V1
VP_IWDG1_VS_IWDG.Mode=IWDG_Activate
VP_LWIP_VS_Enabled.Mode=Enabled
VP_MEMORYMAP_VS_MEMORYMAP.Mode=CurAppReg
VP_PWR_V_PVD_IN.Mode=Mode_PVD_Int
VP_RNG_VS_RNG.Mode=RNG_Activate
VP_RTC_VS_RTC_Activate.Mode=RTC_Enabled
VP_RTC_VS_RTC_Calendar.Mode=RTC_Calendar
VP_SYS_VS_tim6.Mode=TIM6
VP_TIM12_VS_ClockSourceINT.Mode=Internal
VP_TIM15_VS_ClockSourceINT.Mode=Internal
VP_TIM17_VS_ClockSourceINT.Mode=Enable_Timer
VP_TIM1_VS_ClockSourceINT.Mode=Internal
VP_TIM4_VS_ClockSourceINT.Mode=Internal
VP_TIM7_VS_ClockSourceINT.Mode=Enable_Timer
VP_TIM8_VS_ClockSourceINT.Mode=Internal
VP_USB_DEVICE_VS_USB_DEVICE_CDC_FS.Mode=CDC_FS
board=custom

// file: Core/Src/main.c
/* USER CODE BEGIN Header */
/**
  ******************************************************************************
  * @file           : main.c
  * @brief          : Main program body
  ******************************************************************************
  * @attention
  *
  * Copyright (c) 2025 STMicroelectronics.
  * All rights reserved.
  *
  * This software is licensed under terms that can be found in the LICENSE file
  * in the root directory of this software component.
  * If no LICENSE file comes with this software, it is provided AS-IS.
  *
  ******************************************************************************
  */
/* USER CODE END Header */
#include "main.h"
#include "cmsis_os.h"
#include "fatfs.h"
#include "lwip.h"
#include "usb_device.h"

/* USER CODE BEGIN Includes */
#include "battery.h"
#include "drv8874.h"
#include "icm42688p.h"
#include "oled.h"
#include "rx8900ce.h"
#include "ws2812b.h"
#include "buzzer.h"
#include "FreeRTOS_CLI.h"
#include "uxr/client/client.h"
/* USER CODE END Includes */

SD_HandleTypeDef hsd1;

osThreadId startup_taskHandle;
osThreadId cmd_process_taskHandle;
/* USER CODE BEGIN PV */
uart_t uart1_cb;
uart_t uart2_cb;
uart_t uart3_cb;
/* USER CODE END PV */

void SystemClock_Config(void);
void PeriphCommonClock_Config(void);
static void MPU_Config(void);
static void MX_GPIO_Init(void);
static void MX_DMA_Init(void);
static void MX_ADC1_Init(void);
static void MX_CRC_Init(void);
static void MX_I2C1_Init(void);
static void MX_RTC_Init(void);
static void MX_SDMMC1_SD_Init(void);
static void MX_SPI1_Init(void);
static void MX_TIM1_Init(void);
static void MX_TIM2_Init(void);
static void MX_TIM3_Init(void);
static void MX_TIM4_Init(void);
static void MX_TIM8_Init(void);
static void MX_TIM12_Init(void);
static void MX_TIM15_Init(void);
static void MX_UART4_Init(void);
static void MX_USART1_UART_Init(void);
static void MX_USART2_UART_Init(void);
static void MX_USART3_UART_Init(void);
static void MX_LPTIM1_Init(void);
static void MX_LPTIM2_Init(void);
static void MX_ADC3_Init(void);
static void MX_TIM5_Init(void);
static void MX_RNG_Init(void);
static void MX_TIM17_Init(void);
static void MX_IWDG1_Init(void);
static void MX_TIM7_Init(void);
void startup(void const * argument);
void cmd_process(void const * argument);

int main(void)
{

  /* MPU Configuration--------------------------------------------------------*/
  MPU_Config();

  /* Enable the CPU Cache */

  /* Enable I-Cache---------------------------------------------------------*/
  SCB_EnableICache();

  /* Enable D-Cache---------------------------------------------------------*/
  SCB_EnableDCache();

  /* MCU Configuration--------------------------------------------------------*/

  /* Reset of all peripherals, Initializes the Flash interface and the Systick. */
  HAL_Init();

  /** PVD Configuration
  */
  LL_PWR_SetPVDLevel(LL_PWR_PVDLEVEL_6);

  /** Enable the PVD Output
  */
  LL_PWR_EnablePVD();

  /* Configure the system clock */
  SystemClock_Config();

  /* Configure the peripherals common clocks */
  PeriphCommonClock_Config();

  /* Initialize all configured peripherals */
  MX_GPIO_Init();
  MX_DMA_Init();
  MX_ADC1_Init();
  MX_CRC_Init();
  MX_I2C1_Init();
  MX_RTC_Init();
  MX_SDMMC1_SD_Init();
  MX_SPI1_Init();
  MX_TIM1_Init();
  MX_TIM2_Init();
  MX_TIM3_Init();
  MX_TIM4_Init();
  MX_TIM8_Init();
  MX_TIM12_Init();
  MX_TIM15_Init();
  MX_UART4_Init();
  MX_USART1_UART_Init();
  MX_USART2_UART_Init();
  MX_USART3_UART_Init();
  MX_LPTIM1_Init();
  MX_LPTIM2_Init();
  MX_ADC3_Init();
  MX_TIM5_Init();
  MX_RNG_Init();
  MX_TIM17_Init();
  MX_FATFS_Init();
  MX_IWDG1_Init();
  MX_TIM7_Init();
  /* USER CODE BEGIN 2 */
  uart_open(&uart1_cb);
  uart_open(&uart2_cb);
  uart_open(&uart3_cb);
  /* USER CODE END 2 */

  /* Create the thread(s) */
  /* definition and creation of startup_task */
  osThreadDef(startup_task, startup, osPriorityNormal, 0, 1024);
  startup_taskHandle = osThreadCreate(osThread(startup_task), NULL);

  /* definition and creation of cmd_process_task */
  osThreadDef(cmd_process_task, cmd_process, osPriorityNormal, 0, 256);
  cmd_process_taskHandle = osThreadCreate(osThread(cmd_process_task), NULL);

  /* Start scheduler */
  osKernelStart();

  /* We should never get here as control is now taken by the scheduler */

  /* Infinite loop */
  while (1)
  {

  }
}

void SystemClock_Config(void)
{
  LL_FLASH_SetLatency(LL_FLASH_LATENCY_4);
  while(LL_FLASH_GetLatency()!= LL_FLASH_LATENCY_4)
  {
  }
  LL_PWR_ConfigSupply(LL_PWR_LDO_SUPPLY);
  LL_PWR_SetRegulVoltageScaling(LL_PWR_REGU_VOLTAGE_SCALE0);
  while (LL_PWR_IsActiveFlag_VOS() == 0)
  {
  }
  LL_RCC_HSE_EnableBypass();
  LL_RCC_HSE_Enable();

   /* Wait till HSE is ready */
  while(LL_RCC_HSE_IsReady() != 1)
  {

  }
  LL_RCC_HSI48_Enable();

   /* Wait till HSI48 is ready */
  while(LL_RCC_HSI48_IsReady() != 1)
  {

  }
  LL_RCC_LSI_Enable();

   /* Wait till LSI is ready */
  while(LL_RCC_LSI_IsReady() != 1)
  {

  }
  LL_PWR_EnableBkUpAccess();
  LL_RCC_PLL_SetSource(LL_RCC_PLLSOURCE_HSE);
  LL_RCC_PLL1P_Enable();
  LL_RCC_PLL1Q_Enable();
  LL_RCC_PLL1R_Enable();
  LL_RCC_PLL1_SetVCOInputRange(LL_RCC_PLLINPUTRANGE_8_16);
  LL_RCC_PLL1_SetVCOOutputRange(LL_RCC_PLLVCORANGE_WIDE);
  LL_RCC_PLL1_SetM(3);
  LL_RCC_PLL1_SetN(72);
  LL_RCC_PLL1_SetP(2);
  LL_RCC_PLL1_SetQ(15);
  LL_RCC_PLL1_SetR(12);
  LL_RCC_PLL1_Enable();

   /* Wait till PLL is ready */
  while(LL_RCC_PLL1_IsReady() != 1)
  {
  }

   /* Intermediate AHB prescaler 2 when target frequency clock is higher than 80 MHz */
   LL_RCC_SetAHBPrescaler(LL_RCC_AHB_DIV_2);

  LL_RCC_SetSysClkSource(LL_RCC_SYS_CLKSOURCE_PLL1);

   /* Wait till System clock is ready */
  while(LL_RCC_GetSysClkSource() != LL_RCC_SYS_CLKSOURCE_STATUS_PLL1)
  {

  }
  LL_RCC_SetSysPrescaler(LL_RCC_SYSCLK_DIV_1);
  LL_RCC_SetAHBPrescaler(LL_RCC_AHB_DIV_2);
  LL_RCC_SetAPB1Prescaler(LL_RCC_APB1_DIV_2);
  LL_RCC_SetAPB2Prescaler(LL_RCC_APB2_DIV_2);
  LL_RCC_SetAPB3Prescaler(LL_RCC_APB3_DIV_2);
  LL_RCC_SetAPB4Prescaler(LL_RCC_APB4_DIV_2);
  LL_SetSystemCoreClock(480000000);

   /* Update the time base */
  if (HAL_InitTick (TICK_INT_PRIORITY) != HAL_OK)
  {
    Error_Handler();
  }
}

void PeriphCommonClock_Config(void)
{
  LL_RCC_PLL2P_Enable();
  LL_RCC_PLL2_SetVCOInputRange(LL_RCC_PLLINPUTRANGE_8_16);
  LL_RCC_PLL2_SetVCOOutputRange(LL_RCC_PLLVCORANGE_WIDE);
  LL_RCC_PLL2_SetM(3);
  LL_RCC_PLL2_SetN(27);
  LL_RCC_PLL2_SetP(5);
  LL_RCC_PLL2_SetQ(5);
  LL_RCC_PLL2_SetR(5);
  LL_RCC_PLL2_Enable();

   /* Wait till PLL is ready */
  while(LL_RCC_PLL2_IsReady() != 1)
  {
  }

}

static void MX_ADC1_Init(void)
{

  LL_ADC_InitTypeDef ADC_InitStruct = {0};
  LL_ADC_REG_InitTypeDef ADC_REG_InitStruct = {0};
  LL_ADC_CommonInitTypeDef ADC_CommonInitStruct = {0};

  LL_GPIO_InitTypeDef GPIO_InitStruct = {0};

  LL_RCC_SetADCClockSource(LL_RCC_ADC_CLKSOURCE_PLL2P);

  /* Peripheral clock enable */
  LL_AHB1_GRP1_EnableClock(LL_AHB1_GRP1_PERIPH_ADC12);

  LL_AHB4_GRP1_EnableClock(LL_AHB4_GRP1_PERIPH_GPIOC);
  LL_AHB4_GRP1_EnableClock(LL_AHB4_GRP1_PERIPH_GPIOB);
  LL_AHB4_GRP1_EnableClock(LL_AHB4_GRP1_PERIPH_GPIOA);
  /**ADC1 GPIO Configuration
  PC0   ------> ADC1_INP10
  PB0   ------> ADC1_INP9
  PA3   ------> ADC1_INP15
  PB1   ------> ADC1_INP5
  */
  GPIO_InitStruct.Pin = ADC_MOTOR1_Pin;
  GPIO_InitStruct.Mode = LL_GPIO_MODE_ANALOG;
  GPIO_InitStruct.Pull = LL_GPIO_PULL_NO;
  LL_GPIO_Init(ADC_MOTOR1_GPIO_Port, &GPIO_InitStruct);

  GPIO_InitStruct.Pin = ADC_MOTOR2_Pin|ADC_MOTOR3_Pin;
  GPIO_InitStruct.Mode = LL_GPIO_MODE_ANALOG;
  GPIO_InitStruct.Pull = LL_GPIO_PULL_NO;
  LL_GPIO_Init(GPIOB, &GPIO_InitStruct);

  GPIO_InitStruct.Pin = ADC_MOTOR4_Pin;
  GPIO_InitStruct.Mode = LL_GPIO_MODE_ANALOG;
  GPIO_InitStruct.Pull = LL_GPIO_PULL_NO;
  LL_GPIO_Init(ADC_MOTOR4_GPIO_Port, &GPIO_InitStruct);

  /* ADC1 DMA Init */

  /* ADC1 Init */
  LL_DMA_SetPeriphRequest(DMA2, LL_DMA_STREAM_2, LL_DMAMUX1_REQ_ADC1);

  LL_DMA_SetDataTransferDirection(DMA2, LL_DMA_STREAM_2, LL_DMA_DIRECTION_PERIPH_TO_MEMORY);

  LL_DMA_SetStreamPriorityLevel(DMA2, LL_DMA_STREAM_2, LL_DMA_PRIORITY_LOW);

  LL_DMA_SetMode(DMA2, LL_DMA_STREAM_2, LL_DMA_MODE_CIRCULAR);

  LL_DMA_SetPeriphIncMode(DMA2, LL_DMA_STREAM_2, LL_DMA_PERIPH_NOINCREMENT);

  LL_DMA_SetMemoryIncMode(DMA2, LL_DMA_STREAM_2, LL_DMA_MEMORY_INCREMENT);

  LL_DMA_SetPeriphSize(DMA2, LL_DMA_STREAM_2, LL_DMA_PDATAALIGN_HALFWORD);

  LL_DMA_SetMemorySize(DMA2, LL_DMA_STREAM_2, LL_DMA_MDATAALIGN_HALFWORD);

  LL_DMA_DisableFifoMode(DMA2, LL_DMA_STREAM_2);

  /** Common config
  */
  LL_ADC_SetOverSamplingScope(ADC1, LL_ADC_OVS_GRP_REGULAR_CONTINUED);
  LL_ADC_ConfigOverSamplingRatioShift(ADC1, 256, LL_ADC_OVS_SHIFT_RIGHT_8);
  LL_ADC_SetOverSamplingDiscont(ADC1, LL_ADC_OVS_REG_CONT);
  ADC_InitStruct.Resolution = LL_ADC_RESOLUTION_14B;
  ADC_InitStruct.LowPowerMode = LL_ADC_LP_MODE_NONE;
  LL_ADC_Init(ADC1, &ADC_InitStruct);
  ADC_REG_InitStruct.TriggerSource = LL_ADC_REG_TRIG_SOFTWARE;
  ADC_REG_InitStruct.SequencerLength = LL_ADC_REG_SEQ_SCAN_ENABLE_4RANKS;
  ADC_REG_InitStruct.SequencerDiscont = DISABLE;
  ADC_REG_InitStruct.ContinuousMode = LL_ADC_REG_CONV_CONTINUOUS;
  ADC_REG_InitStruct.Overrun = LL_ADC_REG_OVR_DATA_OVERWRITTEN;
  LL_ADC_REG_Init(ADC1, &ADC_REG_InitStruct);
  LL_ADC_REG_SetDataTransferMode(ADC1, LL_ADC_REG_DMA_TRANSFER_UNLIMITED);
  ADC_CommonInitStruct.CommonClock = LL_ADC_CLOCK_ASYNC_DIV1;
  ADC_CommonInitStruct.Multimode = LL_ADC_MULTI_INDEPENDENT;
  LL_ADC_CommonInit(__LL_ADC_COMMON_INSTANCE(ADC1), &ADC_CommonInitStruct);

  /* Disable ADC deep power down (enabled by default after reset state) */
  LL_ADC_DisableDeepPowerDown(ADC1);
  /* Enable ADC internal voltage regulator */
  LL_ADC_EnableInternalRegulator(ADC1);
  /* Delay for ADC internal voltage regulator stabilization. */
  /* Compute number of CPU cycles to wait for, from delay in us. */
  /* Note: Variable divided by 2 to compensate partially */
  /* CPU processing cycles (depends on compilation optimization). */
  /* Note: If system core clock frequency is below 200kHz, wait time */
  /* is only a few CPU processing cycles. */
  __IO uint32_t wait_loop_index;
  wait_loop_index = ((LL_ADC_DELAY_INTERNAL_REGUL_STAB_US * (SystemCoreClock / (100000 * 2))) / 10);
  while(wait_loop_index != 0)
  {
    wait_loop_index--;
  }

  /** Configure Regular Channel
  */
  LL_ADC_REG_SetSequencerRanks(ADC1, LL_ADC_REG_RANK_1, LL_ADC_CHANNEL_10);
  LL_ADC_SetChannelSamplingTime(ADC1, LL_ADC_CHANNEL_10, LL_ADC_SAMPLINGTIME_64CYCLES_5);
  LL_ADC_SetChannelSingleDiff(ADC1, LL_ADC_CHANNEL_10, LL_ADC_SINGLE_ENDED);

  /** Configure Regular Channel
  */
  LL_ADC_REG_SetSequencerRanks(ADC1, LL_ADC_REG_RANK_2, LL_ADC_CHANNEL_9);
  LL_ADC_SetChannelSamplingTime(ADC1, LL_ADC_CHANNEL_9, LL_ADC_SAMPLINGTIME_64CYCLES_5);
  LL_ADC_SetChannelSingleDiff(ADC1, LL_ADC_CHANNEL_9, LL_ADC_SINGLE_ENDED);

  /** Configure Regular Channel
  */
  LL_ADC_REG_SetSequencerRanks(ADC1, LL_ADC_REG_RANK_3, LL_ADC_CHANNEL_5);
  LL_ADC_SetChannelSamplingTime(ADC1, LL_ADC_CHANNEL_5, LL_ADC_SAMPLINGTIME_64CYCLES_5);
  LL_ADC_SetChannelSingleDiff(ADC1, LL_ADC_CHANNEL_5, LL_ADC_SINGLE_ENDED);

  /** Configure Regular Channel
  */
  LL_ADC_REG_SetSequencerRanks(ADC1, LL_ADC_REG_RANK_4, LL_ADC_CHANNEL_15);
  LL_ADC_SetChannelSamplingTime(ADC1, LL_ADC_CHANNEL_15, LL_ADC_SAMPLINGTIME_64CYCLES_5);
  LL_ADC_SetChannelSingleDiff(ADC1, LL_ADC_CHANNEL_15, LL_ADC_SINGLE_ENDED);

}

static void MX_ADC3_Init(void)
{

  LL_ADC_InitTypeDef ADC_InitStruct = {0};
  LL_ADC_REG_InitTypeDef ADC_REG_InitStruct = {0};
  LL_ADC_CommonInitTypeDef ADC_CommonInitStruct = {0};

  LL_RCC_SetADCClockSource(LL_RCC_ADC_CLKSOURCE_PLL2P);

  /* Peripheral clock enable */
  LL_AHB4_GRP1_EnableClock(LL_AHB4_GRP1_PERIPH_ADC3);

  LL_AHB4_GRP1_EnableClock(LL_AHB4_GRP1_PERIPH_GPIOC);
  /**ADC3 GPIO Configuration
  PC3_C   ------> ADC3_INP1
  */
  LL_SYSCFG_OpenAnalogSwitch(LL_SYSCFG_ANALOG_SWITCH_PC3);

  /* ADC3 DMA Init */

  /* ADC3 Init */
  LL_DMA_SetPeriphRequest(DMA2, LL_DMA_STREAM_3, LL_DMAMUX1_REQ_ADC3);

  LL_DMA_SetDataTransferDirection(DMA2, LL_DMA_STREAM_3, LL_DMA_DIRECTION_PERIPH_TO_MEMORY);

  LL_DMA_SetStreamPriorityLevel(DMA2, LL_DMA_STREAM_3, LL_DMA_PRIORITY_LOW);

  LL_DMA_SetMode(DMA2, LL_DMA_STREAM_3, LL_DMA_MODE_CIRCULAR);

  LL_DMA_SetPeriphIncMode(DMA2, LL_DMA_STREAM_3, LL_DMA_PERIPH_NOINCREMENT);

  LL_DMA_SetMemoryIncMode(DMA2, LL_DMA_STREAM_3, LL_DMA_MEMORY_INCREMENT);

  LL_DMA_SetPeriphSize(DMA2, LL_DMA_STREAM_3, LL_DMA_PDATAALIGN_HALFWORD);

  LL_DMA_SetMemorySize(DMA2, LL_DMA_STREAM_3, LL_DMA_MDATAALIGN_HALFWORD);

  LL_DMA_EnableFifoMode(DMA2, LL_DMA_STREAM_3);

  LL_DMA_SetFIFOThreshold(DMA2, LL_DMA_STREAM_3, LL_DMA_FIFOTHRESHOLD_FULL);

  LL_DMA_SetMemoryBurstxfer(DMA2, LL_DMA_STREAM_3, LL_DMA_MBURST_SINGLE);

  LL_DMA_SetPeriphBurstxfer(DMA2, LL_DMA_STREAM_3, LL_DMA_PBURST_SINGLE);

  /** Common config
  */
  LL_ADC_SetOverSamplingScope(ADC3, LL_ADC_OVS_GRP_REGULAR_CONTINUED);
  LL_ADC_ConfigOverSamplingRatioShift(ADC3, 1024, LL_ADC_OVS_SHIFT_RIGHT_10);
  LL_ADC_SetOverSamplingDiscont(ADC3, LL_ADC_OVS_REG_CONT);
  ADC_InitStruct.Resolution = LL_ADC_RESOLUTION_16B;
  ADC_InitStruct.LowPowerMode = LL_ADC_LP_MODE_NONE;
  LL_ADC_Init(ADC3, &ADC_InitStruct);
  ADC_REG_InitStruct.TriggerSource = LL_ADC_REG_TRIG_SOFTWARE;
  ADC_REG_InitStruct.SequencerLength = LL_ADC_REG_SEQ_SCAN_DISABLE;
  ADC_REG_InitStruct.SequencerDiscont = DISABLE;
  ADC_REG_InitStruct.ContinuousMode = LL_ADC_REG_CONV_CONTINUOUS;
  ADC_REG_InitStruct.Overrun = LL_ADC_REG_OVR_DATA_OVERWRITTEN;
  LL_ADC_REG_Init(ADC3, &ADC_REG_InitStruct);
  LL_ADC_REG_SetDataTransferMode(ADC3, LL_ADC_REG_DMA_TRANSFER_UNLIMITED);
  ADC_CommonInitStruct.CommonClock = LL_ADC_CLOCK_ASYNC_DIV1;
  ADC_CommonInitStruct.Multimode = LL_ADC_MULTI_INDEPENDENT;
  LL_ADC_CommonInit(__LL_ADC_COMMON_INSTANCE(ADC3), &ADC_CommonInitStruct);

  /* Disable ADC deep power down (enabled by default after reset state) */
  LL_ADC_DisableDeepPowerDown(ADC3);
  /* Enable ADC internal voltage regulator */
  LL_ADC_EnableInternalRegulator(ADC3);
  /* Delay for ADC internal voltage regulator stabilization. */
  /* Compute number of CPU cycles to wait for, from delay in us. */
  /* Note: Variable divided by 2 to compensate partially */
  /* CPU processing cycles (depends on compilation optimization). */
  /* Note: If system core clock frequency is below 200kHz, wait time */
  /* is only a few CPU processing cycles. */
  __IO uint32_t wait_loop_index;
  wait_loop_index = ((LL_ADC_DELAY_INTERNAL_REGUL_STAB_US * (SystemCoreClock / (100000 * 2))) / 10);
  while(wait_loop_index != 0)
  {
    wait_loop_index--;
  }

  /** Configure Regular Channel
  */
  LL_ADC_REG_SetSequencerRanks(ADC3, LL_ADC_REG_RANK_1, LL_ADC_CHANNEL_1);
  LL_ADC_SetChannelSamplingTime(ADC3, LL_ADC_CHANNEL_1, LL_ADC_SAMPLINGTIME_64CYCLES_5);
  LL_ADC_SetChannelSingleDiff(ADC3, LL_ADC_CHANNEL_1, LL_ADC_SINGLE_ENDED);
  LL_ADC_SetCommonPathInternalCh(__LL_ADC_COMMON_INSTANCE(ADC3), LL_ADC_AWD_CH_TEMPSENSOR_REG|LL_ADC_PATH_INTERNAL_VBAT);

}

static void MX_CRC_Init(void)
{

  /* Peripheral clock enable */
  LL_AHB4_GRP1_EnableClock(LL_AHB4_GRP1_PERIPH_CRC);

  LL_CRC_SetInputDataReverseMode(CRC, LL_CRC_INDATA_REVERSE_NONE);
  LL_CRC_SetOutputDataReverseMode(CRC, LL_CRC_OUTDATA_REVERSE_NONE);
  LL_CRC_SetPolynomialCoef(CRC, LL_CRC_DEFAULT_CRC32_POLY);
  LL_CRC_SetPolynomialSize(CRC, LL_CRC_POLYLENGTH_32B);
  LL_CRC_SetInitialData(CRC, LL_CRC_DEFAULT_CRC_INITVALUE);

}

static void MX_I2C1_Init(void)
{

  LL_I2C_InitTypeDef I2C_InitStruct = {0};

  LL_GPIO_InitTypeDef GPIO_InitStruct = {0};

  LL_RCC_SetI2CClockSource(LL_RCC_I2C123_CLKSOURCE_PCLK1);

  LL_AHB4_GRP1_EnableClock(LL_AHB4_GRP1_PERIPH_GPIOB);
  /**I2C1 GPIO Configuration
  PB7   ------> I2C1_SDA
  PB8   ------> I2C1_SCL
  */
  GPIO_InitStruct.Pin = LL_GPIO_PIN_7|LL_GPIO_PIN_8;
  GPIO_InitStruct.Mode = LL_GPIO_MODE_ALTERNATE;
  GPIO_InitStruct.Speed = LL_GPIO_SPEED_FREQ_HIGH;
  GPIO_InitStruct.OutputType = LL_GPIO_OUTPUT_OPENDRAIN;
  GPIO_InitStruct.Pull = LL_GPIO_PULL_NO;
  GPIO_InitStruct.Alternate = LL_GPIO_AF_4;
  LL_GPIO_Init(GPIOB, &GPIO_InitStruct);

  /* Peripheral clock enable */
  LL_APB1_GRP1_EnableClock(LL_APB1_GRP1_PERIPH_I2C1);

  /** I2C Initialization
  */
  LL_I2C_EnableAutoEndMode(I2C1);
  LL_I2C_SetOwnAddress2(I2C1, 0, LL_I2C_OWNADDRESS2_NOMASK);
  LL_I2C_DisableOwnAddress2(I2C1);
  LL_I2C_DisableGeneralCall(I2C1);
  LL_I2C_EnableClockStretching(I2C1);
  I2C_InitStruct.PeripheralMode = LL_I2C_MODE_I2C;
  I2C_InitStruct.Timing = 0x307075B1;
  I2C_InitStruct.AnalogFilter = LL_I2C_ANALOGFILTER_ENABLE;
  I2C_InitStruct.DigitalFilter = 0;
  I2C_InitStruct.OwnAddress1 = 0;
  I2C_InitStruct.TypeAcknowledge = LL_I2C_ACK;
  I2C_InitStruct.OwnAddrSize = LL_I2C_OWNADDRESS1_7BIT;
  LL_I2C_Init(I2C1, &I2C_InitStruct);

}

static void MX_IWDG1_Init(void)
{

  LL_IWDG_Enable(IWDG1);
  LL_IWDG_EnableWriteAccess(IWDG1);
  LL_IWDG_SetPrescaler(IWDG1, LL_IWDG_PRESCALER_64);
  LL_IWDG_SetReloadCounter(IWDG1, 4095);
  while (LL_IWDG_IsReady(IWDG1) != 1)
  {
  }

  LL_IWDG_ReloadCounter(IWDG1);

}

static void MX_LPTIM1_Init(void)
{

  LL_GPIO_InitTypeDef GPIO_InitStruct = {0};

  LL_RCC_SetLPTIMClockSource(LL_RCC_LPTIM1_CLKSOURCE_PCLK1);

  /* Peripheral clock enable */
  LL_APB1_GRP1_EnableClock(LL_APB1_GRP1_PERIPH_LPTIM1);

  LL_AHB4_GRP1_EnableClock(LL_AHB4_GRP1_PERIPH_GPIOE);
  LL_AHB4_GRP1_EnableClock(LL_AHB4_GRP1_PERIPH_GPIOD);
  /**LPTIM1 GPIO Configuration
  PE1   ------> LPTIM1_IN2
  PD12   ------> LPTIM1_IN1
  */
  GPIO_InitStruct.Pin = ENCB_MOTOR3_Pin;
  GPIO_InitStruct.Mode = LL_GPIO_MODE_ALTERNATE;
  GPIO_InitStruct.Speed = LL_GPIO_SPEED_FREQ_VERY_HIGH;
  GPIO_InitStruct.OutputType = LL_GPIO_OUTPUT_PUSHPULL;
  GPIO_InitStruct.Pull = LL_GPIO_PULL_NO;
  GPIO_InitStruct.Alternate = LL_GPIO_AF_1;
  LL_GPIO_Init(ENCB_MOTOR3_GPIO_Port, &GPIO_InitStruct);

  GPIO_InitStruct.Pin = ENCA_MOTOR3_Pin;
  GPIO_InitStruct.Mode = LL_GPIO_MODE_ALTERNATE;
  GPIO_InitStruct.Speed = LL_GPIO_SPEED_FREQ_VERY_HIGH;
  GPIO_InitStruct.OutputType = LL_GPIO_OUTPUT_PUSHPULL;
  GPIO_InitStruct.Pull = LL_GPIO_PULL_NO;
  GPIO_InitStruct.Alternate = LL_GPIO_AF_1;
  LL_GPIO_Init(ENCA_MOTOR3_GPIO_Port, &GPIO_InitStruct);

  LL_LPTIM_SetClockSource(LPTIM1, LL_LPTIM_CLK_SOURCE_INTERNAL);
  LL_LPTIM_SetPrescaler(LPTIM1, LL_LPTIM_PRESCALER_DIV1);
  LL_LPTIM_SetPolarity(LPTIM1, LL_LPTIM_OUTPUT_POLARITY_REGULAR);
  LL_LPTIM_SetUpdateMode(LPTIM1, LL_LPTIM_UPDATE_MODE_IMMEDIATE);
  LL_LPTIM_SetCounterMode(LPTIM1, LL_LPTIM_COUNTER_MODE_EXTERNAL);
  LL_LPTIM_ConfigClock(LPTIM1, LL_LPTIM_CLK_FILTER_NONE, LL_LPTIM_CLK_POLARITY_RISING);
  LL_LPTIM_TrigSw(LPTIM1);
  LL_LPTIM_SetInput1Src(LPTIM1, LL_LPTIM_INPUT1_SRC_GPIO);
  LL_LPTIM_SetInput2Src(LPTIM1, LL_LPTIM_INPUT2_SRC_GPIO);

}

static void MX_LPTIM2_Init(void)
{

  LL_GPIO_InitTypeDef GPIO_InitStruct = {0};

  LL_RCC_SetLPTIMClockSource(LL_RCC_LPTIM2_CLKSOURCE_PCLK4);

  /* Peripheral clock enable */
  LL_APB4_GRP1_EnableClock(LL_APB4_GRP1_PERIPH_LPTIM2);

  LL_AHB4_GRP1_EnableClock(LL_AHB4_GRP1_PERIPH_GPIOD);
  LL_AHB4_GRP1_EnableClock(LL_AHB4_GRP1_PERIPH_GPIOB);
  /**LPTIM2 GPIO Configuration
  PD11   ------> LPTIM2_IN2
  PB10   ------> LPTIM2_IN1
  */
  GPIO_InitStruct.Pin = ENCB_MOTOR4_Pin;
  GPIO_InitStruct.Mode = LL_GPIO_MODE_ALTERNATE;
  GPIO_InitStruct.Speed = LL_GPIO_SPEED_FREQ_VERY_HIGH;
  GPIO_InitStruct.OutputType = LL_GPIO_OUTPUT_PUSHPULL;
  GPIO_InitStruct.Pull = LL_GPIO_PULL_NO;
  GPIO_InitStruct.Alternate = LL_GPIO_AF_3;
  LL_GPIO_Init(ENCB_MOTOR4_GPIO_Port, &GPIO_InitStruct);

  GPIO_InitStruct.Pin = ENCA_MOTOR4_Pin;
  GPIO_InitStruct.Mode = LL_GPIO_MODE_ALTERNATE;
  GPIO_InitStruct.Speed = LL_GPIO_SPEED_FREQ_VERY_HIGH;
  GPIO_InitStruct.OutputType = LL_GPIO_OUTPUT_PUSHPULL;
  GPIO_InitStruct.Pull = LL_GPIO_PULL_NO;
  GPIO_InitStruct.Alternate = LL_GPIO_AF_3;
  LL_GPIO_Init(ENCA_MOTOR4_GPIO_Port, &GPIO_InitStruct);

  LL_LPTIM_SetClockSource(LPTIM2, LL_LPTIM_CLK_SOURCE_INTERNAL);
  LL_LPTIM_SetPrescaler(LPTIM2, LL_LPTIM_PRESCALER_DIV1);
  LL_LPTIM_SetPolarity(LPTIM2, LL_LPTIM_OUTPUT_POLARITY_REGULAR);
  LL_LPTIM_SetUpdateMode(LPTIM2, LL_LPTIM_UPDATE_MODE_IMMEDIATE);
  LL_LPTIM_SetCounterMode(LPTIM2, LL_LPTIM_COUNTER_MODE_EXTERNAL);
  LL_LPTIM_ConfigClock(LPTIM2, LL_LPTIM_CLK_FILTER_NONE, LL_LPTIM_CLK_POLARITY_RISING);
  LL_LPTIM_TrigSw(LPTIM2);
  LL_LPTIM_SetInput1Src(LPTIM2, LL_LPTIM_INPUT1_SRC_GPIO);

}

static void MX_RNG_Init(void)
{

  LL_RCC_SetRNGClockSource(LL_RCC_RNG_CLKSOURCE_HSI48);

  /* Peripheral clock enable */
  LL_AHB2_GRP1_EnableClock(LL_AHB2_GRP1_PERIPH_RNG);

  LL_RNG_Enable(RNG);

}

static void MX_RTC_Init(void)
{

  LL_RTC_InitTypeDef RTC_InitStruct = {0};
  LL_RTC_TimeTypeDef RTC_TimeStruct = {0};
  LL_RTC_DateTypeDef RTC_DateStruct = {0};

  if(LL_RCC_GetRTCClockSource() != LL_RCC_RTC_CLKSOURCE_HSE)
  {
    LL_RCC_ForceBackupDomainReset();
    LL_RCC_ReleaseBackupDomainReset();
  LL_RCC_SetRTCClockSource(LL_RCC_RTC_CLKSOURCE_HSE);
  }
  LL_RCC_SetRTC_HSEPrescaler(LL_RCC_RTC_HSE_DIV_40);

  /* Peripheral clock enable */
  LL_RCC_EnableRTC();

  RTC_InitStruct.HourFormat = LL_RTC_HOURFORMAT_24HOUR;
  RTC_InitStruct.AsynchPrescaler = 127;
  RTC_InitStruct.SynchPrescaler = 255;
  LL_RTC_Init(RTC, &RTC_InitStruct);

  /** Initialize RTC and set the Time and Date
  */
  RTC_TimeStruct.Hours = 0x0;
  RTC_TimeStruct.Minutes = 0x0;
  RTC_TimeStruct.Seconds = 0x0;

  LL_RTC_TIME_Init(RTC, LL_RTC_FORMAT_BCD, &RTC_TimeStruct);
  RTC_DateStruct.WeekDay = LL_RTC_WEEKDAY_MONDAY;
  RTC_DateStruct.Month = LL_RTC_MONTH_JANUARY;
  RTC_DateStruct.Day = 0x1;
  RTC_DateStruct.Year = 0x0;

  LL_RTC_DATE_Init(RTC, LL_RTC_FORMAT_BCD, &RTC_DateStruct);

}

static void MX_SDMMC1_SD_Init(void)
{

  hsd1.Instance = SDMMC1;
  hsd1.Init.ClockEdge = SDMMC_CLOCK_EDGE_RISING;
  hsd1.Init.ClockPowerSave = SDMMC_CLOCK_POWER_SAVE_DISABLE;
  hsd1.Init.BusWide = SDMMC_BUS_WIDE_4B;
  hsd1.Init.HardwareFlowControl = SDMMC_HARDWARE_FLOW_CONTROL_DISABLE;
  hsd1.Init.ClockDiv = 0;

}

static void MX_SPI1_Init(void)
{

  LL_SPI_InitTypeDef SPI_InitStruct = {0};

  LL_GPIO_InitTypeDef GPIO_InitStruct = {0};

  LL_RCC_SetSPIClockSource(LL_RCC_SPI123_CLKSOURCE_PLL1Q);

  /* Peripheral clock enable */
  LL_APB2_GRP1_EnableClock(LL_APB2_GRP1_PERIPH_SPI1);

  LL_AHB4_GRP1_EnableClock(LL_AHB4_GRP1_PERIPH_GPIOB);
  LL_AHB4_GRP1_EnableClock(LL_AHB4_GRP1_PERIPH_GPIOD);
  LL_AHB4_GRP1_EnableClock(LL_AHB4_GRP1_PERIPH_GPIOA);
  /**SPI1 GPIO Configuration
  PB4 (NJTRST)   ------> SPI1_MISO
  PD7   ------> SPI1_MOSI
  PA4   ------> SPI1_NSS
  PA5   ------> SPI1_SCK
  */
  GPIO_InitStruct.Pin = LL_GPIO_PIN_4;
  GPIO_InitStruct.Mode = LL_GPIO_MODE_ALTERNATE;
  GPIO_InitStruct.Speed = LL_GPIO_SPEED_FREQ_VERY_HIGH;
  GPIO_InitStruct.OutputType = LL_GPIO_OUTPUT_PUSHPULL;
  GPIO_InitStruct.Pull = LL_GPIO_PULL_NO;
  GPIO_InitStruct.Alternate = LL_GPIO_AF_5;
  LL_GPIO_Init(GPIOB, &GPIO_InitStruct);

  GPIO_InitStruct.Pin = LL_GPIO_PIN_7;
  GPIO_InitStruct.Mode = LL_GPIO_MODE_ALTERNATE;
  GPIO_InitStruct.Speed = LL_GPIO_SPEED_FREQ_VERY_HIGH;
  GPIO_InitStruct.OutputType = LL_GPIO_OUTPUT_PUSHPULL;
  GPIO_InitStruct.Pull = LL_GPIO_PULL_NO;
  GPIO_InitStruct.Alternate = LL_GPIO_AF_5;
  LL_GPIO_Init(GPIOD, &GPIO_InitStruct);

  GPIO_InitStruct.Pin = SPI_CS_IMU_Pin|LL_GPIO_PIN_5;
  GPIO_InitStruct.Mode = LL_GPIO_MODE_ALTERNATE;
  GPIO_InitStruct.Speed = LL_GPIO_SPEED_FREQ_VERY_HIGH;
  GPIO_InitStruct.OutputType = LL_GPIO_OUTPUT_PUSHPULL;
  GPIO_InitStruct.Pull = LL_GPIO_PULL_NO;
  GPIO_InitStruct.Alternate = LL_GPIO_AF_5;
  LL_GPIO_Init(GPIOA, &GPIO_InitStruct);

  /* SPI1 DMA Init */

  /* SPI1_RX Init */
  LL_DMA_SetPeriphRequest(DMA2, LL_DMA_STREAM_0, LL_DMAMUX1_REQ_SPI1_RX);

  LL_DMA_SetDataTransferDirection(DMA2, LL_DMA_STREAM_0, LL_DMA_DIRECTION_PERIPH_TO_MEMORY);

  LL_DMA_SetStreamPriorityLevel(DMA2, LL_DMA_STREAM_0, LL_DMA_PRIORITY_LOW);

  LL_DMA_SetMode(DMA2, LL_DMA_STREAM_0, LL_DMA_MODE_NORMAL);

  LL_DMA_SetPeriphIncMode(DMA2, LL_DMA_STREAM_0, LL_DMA_PERIPH_NOINCREMENT);

  LL_DMA_SetMemoryIncMode(DMA2, LL_DMA_STREAM_0, LL_DMA_MEMORY_INCREMENT);

  LL_DMA_SetPeriphSize(DMA2, LL_DMA_STREAM_0, LL_DMA_PDATAALIGN_BYTE);

  LL_DMA_SetMemorySize(DMA2, LL_DMA_STREAM_0, LL_DMA_MDATAALIGN_BYTE);

  LL_DMA_DisableFifoMode(DMA2, LL_DMA_STREAM_0);

  /* SPI1_TX Init */
  LL_DMA_SetPeriphRequest(DMA2, LL_DMA_STREAM_1, LL_DMAMUX1_REQ_SPI1_TX);

  LL_DMA_SetDataTransferDirection(DMA2, LL_DMA_STREAM_1, LL_DMA_DIRECTION_MEMORY_TO_PERIPH);

  LL_DMA_SetStreamPriorityLevel(DMA2, LL_DMA_STREAM_1, LL_DMA_PRIORITY_LOW);

  LL_DMA_SetMode(DMA2, LL_DMA_STREAM_1, LL_DMA_MODE_NORMAL);

  LL_DMA_SetPeriphIncMode(DMA2, LL_DMA_STREAM_1, LL_DMA_PERIPH_NOINCREMENT);

  LL_DMA_SetMemoryIncMode(DMA2, LL_DMA_STREAM_1, LL_DMA_MEMORY_INCREMENT);

  LL_DMA_SetPeriphSize(DMA2, LL_DMA_STREAM_1, LL_DMA_PDATAALIGN_BYTE);

  LL_DMA_SetMemorySize(DMA2, LL_DMA_STREAM_1, LL_DMA_MDATAALIGN_BYTE);

  LL_DMA_DisableFifoMode(DMA2, LL_DMA_STREAM_1);

  /* SPI1 interrupt Init */
  NVIC_SetPriority(SPI1_IRQn, NVIC_EncodePriority(NVIC_GetPriorityGrouping(),5, 0));
  NVIC_EnableIRQ(SPI1_IRQn);

  /* SPI1 parameter configuration*/
  SPI_InitStruct.TransferDirection = LL_SPI_FULL_DUPLEX;
  SPI_InitStruct.Mode = LL_SPI_MODE_MASTER;
  SPI_InitStruct.DataWidth = LL_SPI_DATAWIDTH_8BIT;
  SPI_InitStruct.ClockPolarity = LL_SPI_POLARITY_HIGH;
  SPI_InitStruct.ClockPhase = LL_SPI_PHASE_2EDGE;
  SPI_InitStruct.NSS = LL_SPI_NSS_HARD_OUTPUT;
  SPI_InitStruct.BaudRate = LL_SPI_BAUDRATEPRESCALER_DIV8;
  SPI_InitStruct.BitOrder = LL_SPI_MSB_FIRST;
  SPI_InitStruct.CRCCalculation = LL_SPI_CRCCALCULATION_DISABLE;
  SPI_InitStruct.CRCPoly = 0x0;
  LL_SPI_Init(SPI1, &SPI_InitStruct);
  LL_SPI_SetStandard(SPI1, LL_SPI_PROTOCOL_MOTOROLA);
  LL_SPI_SetFIFOThreshold(SPI1, LL_SPI_FIFO_TH_01DATA);
  LL_SPI_EnableNSSPulseMgt(SPI1);

}

static void MX_TIM1_Init(void)
{

  LL_TIM_InitTypeDef TIM_InitStruct = {0};
  LL_TIM_OC_InitTypeDef TIM_OC_InitStruct = {0};
  LL_TIM_BDTR_InitTypeDef TIM_BDTRInitStruct = {0};

  LL_GPIO_InitTypeDef GPIO_InitStruct = {0};

  /* Peripheral clock enable */
  LL_APB2_GRP1_EnableClock(LL_APB2_GRP1_PERIPH_TIM1);

  TIM_InitStruct.Prescaler = 23;
  TIM_InitStruct.CounterMode = LL_TIM_COUNTERMODE_UP;
  TIM_InitStruct.Autoreload = 9999;
  TIM_InitStruct.ClockDivision = LL_TIM_CLOCKDIVISION_DIV1;
  TIM_InitStruct.RepetitionCounter = 0;
  LL_TIM_Init(TIM1, &TIM_InitStruct);
  LL_TIM_DisableARRPreload(TIM1);
  LL_TIM_SetClockSource(TIM1, LL_TIM_CLOCKSOURCE_INTERNAL);
  LL_TIM_OC_EnablePreload(TIM1, LL_TIM_CHANNEL_CH1);
  TIM_OC_InitStruct.OCMode = LL_TIM_OCMODE_PWM1;
  TIM_OC_InitStruct.OCState = LL_TIM_OCSTATE_DISABLE;
  TIM_OC_InitStruct.OCNState = LL_TIM_OCSTATE_DISABLE;
  TIM_OC_InitStruct.CompareValue = 0;
  TIM_OC_InitStruct.OCPolarity = LL_TIM_OCPOLARITY_HIGH;
  TIM_OC_InitStruct.OCNPolarity = LL_TIM_OCPOLARITY_HIGH;
  TIM_OC_InitStruct.OCIdleState = LL_TIM_OCIDLESTATE_LOW;
  TIM_OC_InitStruct.OCNIdleState = LL_TIM_OCIDLESTATE_LOW;
  LL_TIM_OC_Init(TIM1, LL_TIM_CHANNEL_CH1, &TIM_OC_InitStruct);
  LL_TIM_OC_DisableFast(TIM1, LL_TIM_CHANNEL_CH1);
  LL_TIM_OC_EnablePreload(TIM1, LL_TIM_CHANNEL_CH2);
  LL_TIM_OC_Init(TIM1, LL_TIM_CHANNEL_CH2, &TIM_OC_InitStruct);
  LL_TIM_OC_DisableFast(TIM1, LL_TIM_CHANNEL_CH2);
  LL_TIM_OC_EnablePreload(TIM1, LL_TIM_CHANNEL_CH3);
  LL_TIM_OC_Init(TIM1, LL_TIM_CHANNEL_CH3, &TIM_OC_InitStruct);
  LL_TIM_OC_DisableFast(TIM1, LL_TIM_CHANNEL_CH3);
  LL_TIM_OC_EnablePreload(TIM1, LL_TIM_CHANNEL_CH4);
  LL_TIM_OC_Init(TIM1, LL_TIM_CHANNEL_CH4, &TIM_OC_InitStruct);
  LL_TIM_OC_DisableFast(TIM1, LL_TIM_CHANNEL_CH4);
  LL_TIM_SetTriggerOutput(TIM1, LL_TIM_TRGO_RESET);
  LL_TIM_SetTriggerOutput2(TIM1, LL_TIM_TRGO2_RESET);
  LL_TIM_DisableMasterSlaveMode(TIM1);
  TIM_BDTRInitStruct.OSSRState = LL_TIM_OSSR_DISABLE;
  TIM_BDTRInitStruct.OSSIState = LL_TIM_OSSI_DISABLE;
  TIM_BDTRInitStruct.LockLevel = LL_TIM_LOCKLEVEL_OFF;
  TIM_BDTRInitStruct.DeadTime = 0;
  TIM_BDTRInitStruct.BreakState = LL_TIM_BREAK_DISABLE;
  TIM_BDTRInitStruct.BreakPolarity = LL_TIM_BREAK_POLARITY_HIGH;
  TIM_BDTRInitStruct.BreakFilter = LL_TIM_BREAK_FILTER_FDIV1;
  TIM_BDTRInitStruct.Break2State = LL_TIM_BREAK2_DISABLE;
  TIM_BDTRInitStruct.Break2Polarity = LL_TIM_BREAK2_POLARITY_HIGH;
  TIM_BDTRInitStruct.Break2Filter = LL_TIM_BREAK2_FILTER_FDIV1;
  TIM_BDTRInitStruct.AutomaticOutput = LL_TIM_AUTOMATICOUTPUT_DISABLE;
  LL_TIM_BDTR_Init(TIM1, &TIM_BDTRInitStruct);
  LL_AHB4_GRP1_EnableClock(LL_AHB4_GRP1_PERIPH_GPIOA);
  LL_AHB4_GRP1_EnableClock(LL_AHB4_GRP1_PERIPH_GPIOE);
  /**TIM1 GPIO Configuration
  PA8   ------> TIM1_CH1
  PE14   ------> TIM1_CH4
  PE11   ------> TIM1_CH2
  PE13   ------> TIM1_CH3
  */
  GPIO_InitStruct.Pin = PWM_MOTOR1_Pin;
  GPIO_InitStruct.Mode = LL_GPIO_MODE_ALTERNATE;
  GPIO_InitStruct.Speed = LL_GPIO_SPEED_FREQ_VERY_HIGH;
  GPIO_InitStruct.OutputType = LL_GPIO_OUTPUT_PUSHPULL;
  GPIO_InitStruct.Pull = LL_GPIO_PULL_NO;
  GPIO_InitStruct.Alternate = LL_GPIO_AF_1;
  LL_GPIO_Init(PWM_MOTOR1_GPIO_Port, &GPIO_InitStruct);

  GPIO_InitStruct.Pin = PWM_MOTOR4_Pin|PWM_MOTOR3_Pin|PWM_MOTOR2_Pin;
  GPIO_InitStruct.Mode = LL_GPIO_MODE_ALTERNATE;
  GPIO_InitStruct.Speed = LL_GPIO_SPEED_FREQ_VERY_HIGH;
  GPIO_InitStruct.OutputType = LL_GPIO_OUTPUT_PUSHPULL;
  GPIO_InitStruct.Pull = LL_GPIO_PULL_NO;
  GPIO_InitStruct.Alternate = LL_GPIO_AF_1;
  LL_GPIO_Init(GPIOE, &GPIO_InitStruct);

}

static void MX_TIM2_Init(void)
{

  LL_TIM_InitTypeDef TIM_InitStruct = {0};

  LL_GPIO_InitTypeDef GPIO_InitStruct = {0};

  /* Peripheral clock enable */
  LL_APB1_GRP1_EnableClock(LL_APB1_GRP1_PERIPH_TIM2);

  LL_AHB4_GRP1_EnableClock(LL_AHB4_GRP1_PERIPH_GPIOB);
  LL_AHB4_GRP1_EnableClock(LL_AHB4_GRP1_PERIPH_GPIOA);
  /**TIM2 GPIO Configuration
  PB3 (JTDO/TRACESWO)   ------> TIM2_CH2
  PA15 (JTDI)   ------> TIM2_CH1
  */
  GPIO_InitStruct.Pin = ENCB_MOTOR1_Pin;
  GPIO_InitStruct.Mode = LL_GPIO_MODE_ALTERNATE;
  GPIO_InitStruct.Speed = LL_GPIO_SPEED_FREQ_VERY_HIGH;
  GPIO_InitStruct.OutputType = LL_GPIO_OUTPUT_PUSHPULL;
  GPIO_InitStruct.Pull = LL_GPIO_PULL_NO;
  GPIO_InitStruct.Alternate = LL_GPIO_AF_1;
  LL_GPIO_Init(ENCB_MOTOR1_GPIO_Port, &GPIO_InitStruct);

  GPIO_InitStruct.Pin = ENCA_MOTOR1_Pin;
  GPIO_InitStruct.Mode = LL_GPIO_MODE_ALTERNATE;
  GPIO_InitStruct.Speed = LL_GPIO_SPEED_FREQ_VERY_HIGH;
  GPIO_InitStruct.OutputType = LL_GPIO_OUTPUT_PUSHPULL;
  GPIO_InitStruct.Pull = LL_GPIO_PULL_NO;
  GPIO_InitStruct.Alternate = LL_GPIO_AF_1;
  LL_GPIO_Init(ENCA_MOTOR1_GPIO_Port, &GPIO_InitStruct);

  TIM_InitStruct.Prescaler = 0;
  TIM_InitStruct.CounterMode = LL_TIM_COUNTERMODE_UP;
  TIM_InitStruct.Autoreload = 4294967295;
  TIM_InitStruct.ClockDivision = LL_TIM_CLOCKDIVISION_DIV1;
  LL_TIM_Init(TIM2, &TIM_InitStruct);
  LL_TIM_DisableARRPreload(TIM2);
  LL_TIM_SetEncoderMode(TIM2, LL_TIM_ENCODERMODE_X4_TI12);
  LL_TIM_IC_SetActiveInput(TIM2, LL_TIM_CHANNEL_CH1, LL_TIM_ACTIVEINPUT_DIRECTTI);
  LL_TIM_IC_SetPrescaler(TIM2, LL_TIM_CHANNEL_CH1, LL_TIM_ICPSC_DIV1);
  LL_TIM_IC_SetFilter(TIM2, LL_TIM_CHANNEL_CH1, LL_TIM_IC_FILTER_FDIV1);
  LL_TIM_IC_SetPolarity(TIM2, LL_TIM_CHANNEL_CH1, LL_TIM_IC_POLARITY_RISING);
  LL_TIM_IC_SetActiveInput(TIM2, LL_TIM_CHANNEL_CH2, LL_TIM_ACTIVEINPUT_DIRECTTI);
  LL_TIM_IC_SetPrescaler(TIM2, LL_TIM_CHANNEL_CH2, LL_TIM_ICPSC_DIV1);
  LL_TIM_IC_SetFilter(TIM2, LL_TIM_CHANNEL_CH2, LL_TIM_IC_FILTER_FDIV1);
  LL_TIM_IC_SetPolarity(TIM2, LL_TIM_CHANNEL_CH2, LL_TIM_IC_POLARITY_RISING);
  LL_TIM_SetTriggerOutput(TIM2, LL_TIM_TRGO_RESET);
  LL_TIM_DisableMasterSlaveMode(TIM2);

}

static void MX_TIM3_Init(void)
{

  LL_TIM_InitTypeDef TIM_InitStruct = {0};

  LL_GPIO_InitTypeDef GPIO_InitStruct = {0};

  /* Peripheral clock enable */
  LL_APB1_GRP1_EnableClock(LL_APB1_GRP1_PERIPH_TIM3);

  LL_AHB4_GRP1_EnableClock(LL_AHB4_GRP1_PERIPH_GPIOB);
  LL_AHB4_GRP1_EnableClock(LL_AHB4_GRP1_PERIPH_GPIOA);
  /**TIM3 GPIO Configuration
  PB5   ------> TIM3_CH2
  PA6   ------> TIM3_CH1
  */
  GPIO_InitStruct.Pin = ENCB_MOTOR2_Pin;
  GPIO_InitStruct.Mode = LL_GPIO_MODE_ALTERNATE;
  GPIO_InitStruct.Speed = LL_GPIO_SPEED_FREQ_VERY_HIGH;
  GPIO_InitStruct.OutputType = LL_GPIO_OUTPUT_PUSHPULL;
  GPIO_InitStruct.Pull = LL_GPIO_PULL_NO;
  GPIO_InitStruct.Alternate = LL_GPIO_AF_2;
  LL_GPIO_Init(ENCB_MOTOR2_GPIO_Port, &GPIO_InitStruct);

  GPIO_InitStruct.Pin = ENCA_MOTOR2_Pin;
  GPIO_InitStruct.Mode = LL_GPIO_MODE_ALTERNATE;
  GPIO_InitStruct.Speed = LL_GPIO_SPEED_FREQ_VERY_HIGH;
  GPIO_InitStruct.OutputType = LL_GPIO_OUTPUT_PUSHPULL;
  GPIO_InitStruct.Pull = LL_GPIO_PULL_NO;
  GPIO_InitStruct.Alternate = LL_GPIO_AF_2;
  LL_GPIO_Init(ENCA_MOTOR2_GPIO_Port, &GPIO_InitStruct);

  TIM_InitStruct.Prescaler = 0;
  TIM_InitStruct.CounterMode = LL_TIM_COUNTERMODE_UP;
  TIM_InitStruct.Autoreload = 65535;
  TIM_InitStruct.ClockDivision = LL_TIM_CLOCKDIVISION_DIV1;
  LL_TIM_Init(TIM3, &TIM_InitStruct);
  LL_TIM_DisableARRPreload(TIM3);
  LL_TIM_SetEncoderMode(TIM3, LL_TIM_ENCODERMODE_X4_TI12);
  LL_TIM_IC_SetActiveInput(TIM3, LL_TIM_CHANNEL_CH1, LL_TIM_ACTIVEINPUT_DIRECTTI);
  LL_TIM_IC_SetPrescaler(TIM3, LL_TIM_CHANNEL_CH1, LL_TIM_ICPSC_DIV1);
  LL_TIM_IC_SetFilter(TIM3, LL_TIM_CHANNEL_CH1, LL_TIM_IC_FILTER_FDIV1);
  LL_TIM_IC_SetPolarity(TIM3, LL_TIM_CHANNEL_CH1, LL_TIM_IC_POLARITY_RISING);
  LL_TIM_IC_SetActiveInput(TIM3, LL_TIM_CHANNEL_CH2, LL_TIM_ACTIVEINPUT_DIRECTTI);
  LL_TIM_IC_SetPrescaler(TIM3, LL_TIM_CHANNEL_CH2, LL_TIM_ICPSC_DIV1);
  LL_TIM_IC_SetFilter(TIM3, LL_TIM_CHANNEL_CH2, LL_TIM_IC_FILTER_FDIV1);
  LL_TIM_IC_SetPolarity(TIM3, LL_TIM_CHANNEL_CH2, LL_TIM_IC_POLARITY_RISING);
  LL_TIM_SetTriggerOutput(TIM3, LL_TIM_TRGO_RESET);
  LL_TIM_DisableMasterSlaveMode(TIM3);

}

static void MX_TIM4_Init(void)
{

  LL_TIM_InitTypeDef TIM_InitStruct = {0};
  LL_TIM_OC_InitTypeDef TIM_OC_InitStruct = {0};

  LL_GPIO_InitTypeDef GPIO_InitStruct = {0};

  /* Peripheral clock enable */
  LL_APB1_GRP1_EnableClock(LL_APB1_GRP1_PERIPH_TIM4);

  TIM_InitStruct.Prescaler = 0;
  TIM_InitStruct.CounterMode = LL_TIM_COUNTERMODE_UP;
  TIM_InitStruct.Autoreload = 65535;
  TIM_InitStruct.ClockDivision = LL_TIM_CLOCKDIVISION_DIV1;
  LL_TIM_Init(TIM4, &TIM_InitStruct);
  LL_TIM_DisableARRPreload(TIM4);
  LL_TIM_SetClockSource(TIM4, LL_TIM_CLOCKSOURCE_INTERNAL);
  LL_TIM_OC_EnablePreload(TIM4, LL_TIM_CHANNEL_CH1);
  TIM_OC_InitStruct.OCMode = LL_TIM_OCMODE_PWM1;
  TIM_OC_InitStruct.OCState = LL_TIM_OCSTATE_DISABLE;
  TIM_OC_InitStruct.OCNState = LL_TIM_OCSTATE_DISABLE;
  TIM_OC_InitStruct.CompareValue = 0;
  TIM_OC_InitStruct.OCPolarity = LL_TIM_OCPOLARITY_HIGH;
  LL_TIM_OC_Init(TIM4, LL_TIM_CHANNEL_CH1, &TIM_OC_InitStruct);
  LL_TIM_OC_DisableFast(TIM4, LL_TIM_CHANNEL_CH1);
  LL_TIM_OC_EnablePreload(TIM4, LL_TIM_CHANNEL_CH2);
  LL_TIM_OC_Init(TIM4, LL_TIM_CHANNEL_CH2, &TIM_OC_InitStruct);
  LL_TIM_OC_DisableFast(TIM4, LL_TIM_CHANNEL_CH2);
  LL_TIM_OC_EnablePreload(TIM4, LL_TIM_CHANNEL_CH3);
  LL_TIM_OC_Init(TIM4, LL_TIM_CHANNEL_CH3, &TIM_OC_InitStruct);
  LL_TIM_OC_DisableFast(TIM4, LL_TIM_CHANNEL_CH3);
  LL_TIM_OC_EnablePreload(TIM4, LL_TIM_CHANNEL_CH4);
  LL_TIM_OC_Init(TIM4, LL_TIM_CHANNEL_CH4, &TIM_OC_InitStruct);
  LL_TIM_OC_DisableFast(TIM4, LL_TIM_CHANNEL_CH4);
  LL_TIM_SetTriggerOutput(TIM4, LL_TIM_TRGO_RESET);
  LL_TIM_DisableMasterSlaveMode(TIM4);
  LL_AHB4_GRP1_EnableClock(LL_AHB4_GRP1_PERIPH_GPIOB);
  LL_AHB4_GRP1_EnableClock(LL_AHB4_GRP1_PERIPH_GPIOD);
  /**TIM4 GPIO Configuration
  PB6   ------> TIM4_CH1
  PD15   ------> TIM4_CH4
  PD14   ------> TIM4_CH3
  PD13   ------> TIM4_CH2
  */
  GPIO_InitStruct.Pin = FSYNC1_Pin;
  GPIO_InitStruct.Mode = LL_GPIO_MODE_ALTERNATE;
  GPIO_InitStruct.Speed = LL_GPIO_SPEED_FREQ_VERY_HIGH;
  GPIO_InitStruct.OutputType = LL_GPIO_OUTPUT_PUSHPULL;
  GPIO_InitStruct.Pull = LL_GPIO_PULL_NO;
  GPIO_InitStruct.Alternate = LL_GPIO_AF_2;
  LL_GPIO_Init(FSYNC1_GPIO_Port, &GPIO_InitStruct);

  GPIO_InitStruct.Pin = STROBE2_Pin|STROBE1_Pin|FSYNC2_Pin;
  GPIO_InitStruct.Mode = LL_GPIO_MODE_ALTERNATE;
  GPIO_InitStruct.Speed = LL_GPIO_SPEED_FREQ_VERY_HIGH;
  GPIO_InitStruct.OutputType = LL_GPIO_OUTPUT_PUSHPULL;
  GPIO_InitStruct.Pull = LL_GPIO_PULL_NO;
  GPIO_InitStruct.Alternate = LL_GPIO_AF_2;
  LL_GPIO_Init(GPIOD, &GPIO_InitStruct);

  LL_SYSCFG_EnableFastModePlus(LL_SYSCFG_I2C_FASTMODEPLUS_PB6);

}

static void MX_TIM5_Init(void)
{

  LL_TIM_InitTypeDef TIM_InitStruct = {0};

  LL_GPIO_InitTypeDef GPIO_InitStruct = {0};

  /* Peripheral clock enable */
  LL_APB1_GRP1_EnableClock(LL_APB1_GRP1_PERIPH_TIM5);

  LL_AHB4_GRP1_EnableClock(LL_AHB4_GRP1_PERIPH_GPIOA);
  /**TIM5 GPIO Configuration
  PA0   ------> TIM5_CH1
  */
  GPIO_InitStruct.Pin = GPS_PPS_Pin;
  GPIO_InitStruct.Mode = LL_GPIO_MODE_ALTERNATE;
  GPIO_InitStruct.Speed = LL_GPIO_SPEED_FREQ_VERY_HIGH;
  GPIO_InitStruct.OutputType = LL_GPIO_OUTPUT_PUSHPULL;
  GPIO_InitStruct.Pull = LL_GPIO_PULL_NO;
  GPIO_InitStruct.Alternate = LL_GPIO_AF_2;
  LL_GPIO_Init(GPS_PPS_GPIO_Port, &GPIO_InitStruct);

  TIM_InitStruct.Prescaler = 0;
  TIM_InitStruct.CounterMode = LL_TIM_COUNTERMODE_UP;
  TIM_InitStruct.Autoreload = 4294967295;
  TIM_InitStruct.ClockDivision = LL_TIM_CLOCKDIVISION_DIV1;
  LL_TIM_Init(TIM5, &TIM_InitStruct);
  LL_TIM_DisableARRPreload(TIM5);
  LL_TIM_SetTriggerOutput(TIM5, LL_TIM_TRGO_RESET);
  LL_TIM_DisableMasterSlaveMode(TIM5);
  LL_TIM_IC_SetActiveInput(TIM5, LL_TIM_CHANNEL_CH1, LL_TIM_ACTIVEINPUT_DIRECTTI);
  LL_TIM_IC_SetPrescaler(TIM5, LL_TIM_CHANNEL_CH1, LL_TIM_ICPSC_DIV1);
  LL_TIM_IC_SetFilter(TIM5, LL_TIM_CHANNEL_CH1, LL_TIM_IC_FILTER_FDIV1);
  LL_TIM_IC_SetPolarity(TIM5, LL_TIM_CHANNEL_CH1, LL_TIM_IC_POLARITY_RISING);

}

static void MX_TIM7_Init(void)
{

  LL_TIM_InitTypeDef TIM_InitStruct = {0};

  /* Peripheral clock enable */
  LL_APB1_GRP1_EnableClock(LL_APB1_GRP1_PERIPH_TIM7);

  /* TIM7 interrupt Init */
  NVIC_SetPriority(TIM7_IRQn, NVIC_EncodePriority(NVIC_GetPriorityGrouping(),5, 0));
  NVIC_EnableIRQ(TIM7_IRQn);

  TIM_InitStruct.Prescaler = 239;
  TIM_InitStruct.CounterMode = LL_TIM_COUNTERMODE_UP;
  TIM_InitStruct.Autoreload = 65535;
  LL_TIM_Init(TIM7, &TIM_InitStruct);
  LL_TIM_DisableARRPreload(TIM7);
  LL_TIM_SetTriggerOutput(TIM7, LL_TIM_TRGO_RESET);
  LL_TIM_DisableMasterSlaveMode(TIM7);

}

static void MX_TIM8_Init(void)
{

  LL_TIM_InitTypeDef TIM_InitStruct = {0};
  LL_TIM_OC_InitTypeDef TIM_OC_InitStruct = {0};
  LL_TIM_BDTR_InitTypeDef TIM_BDTRInitStruct = {0};

  LL_GPIO_InitTypeDef GPIO_InitStruct = {0};

  /* Peripheral clock enable */
  LL_APB2_GRP1_EnableClock(LL_APB2_GRP1_PERIPH_TIM8);

  TIM_InitStruct.Prescaler = 0;
  TIM_InitStruct.CounterMode = LL_TIM_COUNTERMODE_UP;
  TIM_InitStruct.Autoreload = 65535;
  TIM_InitStruct.ClockDivision = LL_TIM_CLOCKDIVISION_DIV1;
  TIM_InitStruct.RepetitionCounter = 0;
  LL_TIM_Init(TIM8, &TIM_InitStruct);
  LL_TIM_DisableARRPreload(TIM8);
  LL_TIM_SetClockSource(TIM8, LL_TIM_CLOCKSOURCE_INTERNAL);
  LL_TIM_OC_EnablePreload(TIM8, LL_TIM_CHANNEL_CH1);
  TIM_OC_InitStruct.OCMode = LL_TIM_OCMODE_PWM1;
  TIM_OC_InitStruct.OCState = LL_TIM_OCSTATE_DISABLE;
  TIM_OC_InitStruct.OCNState = LL_TIM_OCSTATE_DISABLE;
  TIM_OC_InitStruct.CompareValue = 0;
  TIM_OC_InitStruct.OCPolarity = LL_TIM_OCPOLARITY_HIGH;
  TIM_OC_InitStruct.OCNPolarity = LL_TIM_OCPOLARITY_HIGH;
  TIM_OC_InitStruct.OCIdleState = LL_TIM_OCIDLESTATE_LOW;
  TIM_OC_InitStruct.OCNIdleState = LL_TIM_OCIDLESTATE_LOW;
  LL_TIM_OC_Init(TIM8, LL_TIM_CHANNEL_CH1, &TIM_OC_InitStruct);
  LL_TIM_OC_DisableFast(TIM8, LL_TIM_CHANNEL_CH1);
  LL_TIM_OC_EnablePreload(TIM8, LL_TIM_CHANNEL_CH2);
  LL_TIM_OC_Init(TIM8, LL_TIM_CHANNEL_CH2, &TIM_OC_InitStruct);
  LL_TIM_OC_DisableFast(TIM8, LL_TIM_CHANNEL_CH2);
  LL_TIM_SetTriggerOutput(TIM8, LL_TIM_TRGO_RESET);
  LL_TIM_SetTriggerOutput2(TIM8, LL_TIM_TRGO2_RESET);
  LL_TIM_DisableMasterSlaveMode(TIM8);
  TIM_BDTRInitStruct.OSSRState = LL_TIM_OSSR_DISABLE;
  TIM_BDTRInitStruct.OSSIState = LL_TIM_OSSI_DISABLE;
  TIM_BDTRInitStruct.LockLevel = LL_TIM_LOCKLEVEL_OFF;
  TIM_BDTRInitStruct.DeadTime = 0;
  TIM_BDTRInitStruct.BreakState = LL_TIM_BREAK_DISABLE;
  TIM_BDTRInitStruct.BreakPolarity = LL_TIM_BREAK_POLARITY_HIGH;
  TIM_BDTRInitStruct.BreakFilter = LL_TIM_BREAK_FILTER_FDIV1;
  TIM_BDTRInitStruct.Break2State = LL_TIM_BREAK2_DISABLE;
  TIM_BDTRInitStruct.Break2Polarity = LL_TIM_BREAK2_POLARITY_HIGH;
  TIM_BDTRInitStruct.Break2Filter = LL_TIM_BREAK2_FILTER_FDIV1;
  TIM_BDTRInitStruct.AutomaticOutput = LL_TIM_AUTOMATICOUTPUT_DISABLE;
  LL_TIM_BDTR_Init(TIM8, &TIM_BDTRInitStruct);
  LL_AHB4_GRP1_EnableClock(LL_AHB4_GRP1_PERIPH_GPIOC);
  /**TIM8 GPIO Configuration
  PC7   ------> TIM8_CH2
  PC6   ------> TIM8_CH1
  */
  GPIO_InitStruct.Pin = PWM_SERVO2_Pin|PWM_SERVO1_Pin;
  GPIO_InitStruct.Mode = LL_GPIO_MODE_ALTERNATE;
  GPIO_InitStruct.Speed = LL_GPIO_SPEED_FREQ_VERY_HIGH;
  GPIO_InitStruct.OutputType = LL_GPIO_OUTPUT_PUSHPULL;
  GPIO_InitStruct.Pull = LL_GPIO_PULL_NO;
  GPIO_InitStruct.Alternate = LL_GPIO_AF_3;
  LL_GPIO_Init(GPIOC, &GPIO_InitStruct);

}

static void MX_TIM12_Init(void)
{

  LL_TIM_InitTypeDef TIM_InitStruct = {0};
  LL_TIM_OC_InitTypeDef TIM_OC_InitStruct = {0};

  LL_GPIO_InitTypeDef GPIO_InitStruct = {0};

  /* Peripheral clock enable */
  LL_APB1_GRP1_EnableClock(LL_APB1_GRP1_PERIPH_TIM12);

  TIM_InitStruct.Prescaler = 0;
  TIM_InitStruct.CounterMode = LL_TIM_COUNTERMODE_UP;
  TIM_InitStruct.Autoreload = 65535;
  TIM_InitStruct.ClockDivision = LL_TIM_CLOCKDIVISION_DIV1;
  LL_TIM_Init(TIM12, &TIM_InitStruct);
  LL_TIM_DisableARRPreload(TIM12);
  LL_TIM_SetClockSource(TIM12, LL_TIM_CLOCKSOURCE_INTERNAL);
  LL_TIM_OC_EnablePreload(TIM12, LL_TIM_CHANNEL_CH1);
  TIM_OC_InitStruct.OCMode = LL_TIM_OCMODE_PWM1;
  TIM_OC_InitStruct.OCState = LL_TIM_OCSTATE_DISABLE;
  TIM_OC_InitStruct.OCNState = LL_TIM_OCSTATE_DISABLE;
  TIM_OC_InitStruct.CompareValue = 0;
  TIM_OC_InitStruct.OCPolarity = LL_TIM_OCPOLARITY_HIGH;
  LL_TIM_OC_Init(TIM12, LL_TIM_CHANNEL_CH1, &TIM_OC_InitStruct);
  LL_TIM_OC_DisableFast(TIM12, LL_TIM_CHANNEL_CH1);
  LL_TIM_OC_EnablePreload(TIM12, LL_TIM_CHANNEL_CH2);
  LL_TIM_OC_Init(TIM12, LL_TIM_CHANNEL_CH2, &TIM_OC_InitStruct);
  LL_TIM_OC_DisableFast(TIM12, LL_TIM_CHANNEL_CH2);
  LL_TIM_SetTriggerOutput(TIM12, LL_TIM_TRGO_RESET);
  LL_TIM_DisableMasterSlaveMode(TIM12);
  LL_AHB4_GRP1_EnableClock(LL_AHB4_GRP1_PERIPH_GPIOB);
  /**TIM12 GPIO Configuration
  PB15   ------> TIM12_CH2
  PB14   ------> TIM12_CH1
  */
  GPIO_InitStruct.Pin = PWM_SERVO4_Pin|PWM_SERVO3_Pin;
  GPIO_InitStruct.Mode = LL_GPIO_MODE_ALTERNATE;
  GPIO_InitStruct.Speed = LL_GPIO_SPEED_FREQ_VERY_HIGH;
  GPIO_InitStruct.OutputType = LL_GPIO_OUTPUT_PUSHPULL;
  GPIO_InitStruct.Pull = LL_GPIO_PULL_NO;
  GPIO_InitStruct.Alternate = LL_GPIO_AF_2;
  LL_GPIO_Init(GPIOB, &GPIO_InitStruct);

}

static void MX_TIM15_Init(void)
{

  LL_TIM_InitTypeDef TIM_InitStruct = {0};
  LL_TIM_OC_InitTypeDef TIM_OC_InitStruct = {0};
  LL_TIM_BDTR_InitTypeDef TIM_BDTRInitStruct = {0};

  LL_GPIO_InitTypeDef GPIO_InitStruct = {0};

  /* Peripheral clock enable */
  LL_APB2_GRP1_EnableClock(LL_APB2_GRP1_PERIPH_TIM15);

  TIM_InitStruct.Prescaler = 239;
  TIM_InitStruct.CounterMode = LL_TIM_COUNTERMODE_UP;
  TIM_InitStruct.Autoreload = 65535;
  TIM_InitStruct.ClockDivision = LL_TIM_CLOCKDIVISION_DIV1;
  TIM_InitStruct.RepetitionCounter = 0;
  LL_TIM_Init(TIM15, &TIM_InitStruct);
  LL_TIM_EnableARRPreload(TIM15);
  LL_TIM_SetClockSource(TIM15, LL_TIM_CLOCKSOURCE_INTERNAL);
  LL_TIM_OC_EnablePreload(TIM15, LL_TIM_CHANNEL_CH1);
  TIM_OC_InitStruct.OCMode = LL_TIM_OCMODE_PWM1;
  TIM_OC_InitStruct.OCState = LL_TIM_OCSTATE_DISABLE;
  TIM_OC_InitStruct.OCNState = LL_TIM_OCSTATE_DISABLE;
  TIM_OC_InitStruct.CompareValue = 0;
  TIM_OC_InitStruct.OCPolarity = LL_TIM_OCPOLARITY_HIGH;
  TIM_OC_InitStruct.OCNPolarity = LL_TIM_OCPOLARITY_HIGH;
  TIM_OC_InitStruct.OCIdleState = LL_TIM_OCIDLESTATE_LOW;
  TIM_OC_InitStruct.OCNIdleState = LL_TIM_OCIDLESTATE_LOW;
  LL_TIM_OC_Init(TIM15, LL_TIM_CHANNEL_CH1, &TIM_OC_InitStruct);
  LL_TIM_OC_DisableFast(TIM15, LL_TIM_CHANNEL_CH1);
  LL_TIM_SetTriggerOutput(TIM15, LL_TIM_TRGO_RESET);
  LL_TIM_DisableMasterSlaveMode(TIM15);
  TIM_BDTRInitStruct.OSSRState = LL_TIM_OSSR_DISABLE;
  TIM_BDTRInitStruct.OSSIState = LL_TIM_OSSI_DISABLE;
  TIM_BDTRInitStruct.LockLevel = LL_TIM_LOCKLEVEL_OFF;
  TIM_BDTRInitStruct.DeadTime = 0;
  TIM_BDTRInitStruct.BreakState = LL_TIM_BREAK_DISABLE;
  TIM_BDTRInitStruct.BreakPolarity = LL_TIM_BREAK_POLARITY_HIGH;
  TIM_BDTRInitStruct.BreakFilter = LL_TIM_BREAK_FILTER_FDIV1;
  TIM_BDTRInitStruct.AutomaticOutput = LL_TIM_AUTOMATICOUTPUT_DISABLE;
  LL_TIM_BDTR_Init(TIM15, &TIM_BDTRInitStruct);
  LL_AHB4_GRP1_EnableClock(LL_AHB4_GRP1_PERIPH_GPIOE);
  /**TIM15 GPIO Configuration
  PE5   ------> TIM15_CH1
  */
  GPIO_InitStruct.Pin = PWM_BUZZER_Pin;
  GPIO_InitStruct.Mode = LL_GPIO_MODE_ALTERNATE;
  GPIO_InitStruct.Speed = LL_GPIO_SPEED_FREQ_VERY_HIGH;
  GPIO_InitStruct.OutputType = LL_GPIO_OUTPUT_PUSHPULL;
  GPIO_InitStruct.Pull = LL_GPIO_PULL_NO;
  GPIO_InitStruct.Alternate = LL_GPIO_AF_4;
  LL_GPIO_Init(PWM_BUZZER_GPIO_Port, &GPIO_InitStruct);

}

static void MX_TIM17_Init(void)
{

  LL_TIM_InitTypeDef TIM_InitStruct = {0};
  LL_TIM_OC_InitTypeDef TIM_OC_InitStruct = {0};
  LL_TIM_BDTR_InitTypeDef TIM_BDTRInitStruct = {0};

  LL_GPIO_InitTypeDef GPIO_InitStruct = {0};

  /* Peripheral clock enable */
  LL_APB2_GRP1_EnableClock(LL_APB2_GRP1_PERIPH_TIM17);

  /* TIM17 DMA Init */

  /* TIM17_CH1 Init */
  LL_DMA_SetPeriphRequest(DMA2, LL_DMA_STREAM_4, LL_DMAMUX1_REQ_TIM17_CH1);

  LL_DMA_SetDataTransferDirection(DMA2, LL_DMA_STREAM_4, LL_DMA_DIRECTION_MEMORY_TO_PERIPH);

  LL_DMA_SetStreamPriorityLevel(DMA2, LL_DMA_STREAM_4, LL_DMA_PRIORITY_LOW);

  LL_DMA_SetMode(DMA2, LL_DMA_STREAM_4, LL_DMA_MODE_NORMAL);

  LL_DMA_SetPeriphIncMode(DMA2, LL_DMA_STREAM_4, LL_DMA_PERIPH_NOINCREMENT);

  LL_DMA_SetMemoryIncMode(DMA2, LL_DMA_STREAM_4, LL_DMA_MEMORY_INCREMENT);

  LL_DMA_SetPeriphSize(DMA2, LL_DMA_STREAM_4, LL_DMA_PDATAALIGN_HALFWORD);

  LL_DMA_SetMemorySize(DMA2, LL_DMA_STREAM_4, LL_DMA_MDATAALIGN_HALFWORD);

  LL_DMA_DisableFifoMode(DMA2, LL_DMA_STREAM_4);

  TIM_InitStruct.Prescaler = 0;
  TIM_InitStruct.CounterMode = LL_TIM_COUNTERMODE_UP;
  TIM_InitStruct.Autoreload = 299;
  TIM_InitStruct.ClockDivision = LL_TIM_CLOCKDIVISION_DIV1;
  TIM_InitStruct.RepetitionCounter = 0;
  LL_TIM_Init(TIM17, &TIM_InitStruct);
  LL_TIM_DisableARRPreload(TIM17);
  LL_TIM_OC_EnablePreload(TIM17, LL_TIM_CHANNEL_CH1);
  TIM_OC_InitStruct.OCMode = LL_TIM_OCMODE_PWM1;
  TIM_OC_InitStruct.OCState = LL_TIM_OCSTATE_DISABLE;
  TIM_OC_InitStruct.OCNState = LL_TIM_OCSTATE_DISABLE;
  TIM_OC_InitStruct.CompareValue = 0;
  TIM_OC_InitStruct.OCPolarity = LL_TIM_OCPOLARITY_HIGH;
  TIM_OC_InitStruct.OCNPolarity = LL_TIM_OCPOLARITY_HIGH;
  TIM_OC_InitStruct.OCIdleState = LL_TIM_OCIDLESTATE_LOW;
  TIM_OC_InitStruct.OCNIdleState = LL_TIM_OCIDLESTATE_LOW;
  LL_TIM_OC_Init(TIM17, LL_TIM_CHANNEL_CH1, &TIM_OC_InitStruct);
  LL_TIM_OC_DisableFast(TIM17, LL_TIM_CHANNEL_CH1);
  TIM_BDTRInitStruct.OSSRState = LL_TIM_OSSR_DISABLE;
  TIM_BDTRInitStruct.OSSIState = LL_TIM_OSSI_DISABLE;
  TIM_BDTRInitStruct.LockLevel = LL_TIM_LOCKLEVEL_OFF;
  TIM_BDTRInitStruct.DeadTime = 0;
  TIM_BDTRInitStruct.BreakState = LL_TIM_BREAK_DISABLE;
  TIM_BDTRInitStruct.BreakPolarity = LL_TIM_BREAK_POLARITY_HIGH;
  TIM_BDTRInitStruct.BreakFilter = LL_TIM_BREAK_FILTER_FDIV1;
  TIM_BDTRInitStruct.AutomaticOutput = LL_TIM_AUTOMATICOUTPUT_DISABLE;
  LL_TIM_BDTR_Init(TIM17, &TIM_BDTRInitStruct);
  LL_AHB4_GRP1_EnableClock(LL_AHB4_GRP1_PERIPH_GPIOB);
  /**TIM17 GPIO Configuration
  PB9   ------> TIM17_CH1
  */
  GPIO_InitStruct.Pin = PWM_RGB_Pin;
  GPIO_InitStruct.Mode = LL_GPIO_MODE_ALTERNATE;
  GPIO_InitStruct.Speed = LL_GPIO_SPEED_FREQ_VERY_HIGH;
  GPIO_InitStruct.OutputType = LL_GPIO_OUTPUT_PUSHPULL;
  GPIO_InitStruct.Pull = LL_GPIO_PULL_NO;
  GPIO_InitStruct.Alternate = LL_GPIO_AF_1;
  LL_GPIO_Init(PWM_RGB_GPIO_Port, &GPIO_InitStruct);

  LL_SYSCFG_EnableFastModePlus(LL_SYSCFG_I2C_FASTMODEPLUS_PB9);

}

static void MX_UART4_Init(void)
{

  LL_USART_InitTypeDef UART_InitStruct = {0};

  LL_GPIO_InitTypeDef GPIO_InitStruct = {0};

  LL_RCC_SetUSARTClockSource(LL_RCC_USART234578_CLKSOURCE_PCLK1);

  /* Peripheral clock enable */
  LL_APB1_GRP1_EnableClock(LL_APB1_GRP1_PERIPH_UART4);

  LL_AHB4_GRP1_EnableClock(LL_AHB4_GRP1_PERIPH_GPIOD);
  /**UART4 GPIO Configuration
  PD0   ------> UART4_RX
  PD1   ------> UART4_TX
  */
  GPIO_InitStruct.Pin = LL_GPIO_PIN_0|LL_GPIO_PIN_1;
  GPIO_InitStruct.Mode = LL_GPIO_MODE_ALTERNATE;
  GPIO_InitStruct.Speed = LL_GPIO_SPEED_FREQ_VERY_HIGH;
  GPIO_InitStruct.OutputType = LL_GPIO_OUTPUT_PUSHPULL;
  GPIO_InitStruct.Pull = LL_GPIO_PULL_NO;
  GPIO_InitStruct.Alternate = LL_GPIO_AF_8;
  LL_GPIO_Init(GPIOD, &GPIO_InitStruct);

  LL_SYSCFG_EnableFastModePlus(LL_SYSCFG_I2C_FASTMODEPLUS_PB8);

  /* UART4 DMA Init */

  /* UART4_RX Init */
  LL_DMA_SetPeriphRequest(DMA1, LL_DMA_STREAM_6, LL_DMAMUX1_REQ_UART4_RX);

  LL_DMA_SetDataTransferDirection(DMA1, LL_DMA_STREAM_6, LL_DMA_DIRECTION_PERIPH_TO_MEMORY);

  LL_DMA_SetStreamPriorityLevel(DMA1, LL_DMA_STREAM_6, LL_DMA_PRIORITY_LOW);

  LL_DMA_SetMode(DMA1, LL_DMA_STREAM_6, LL_DMA_MODE_NORMAL);

  LL_DMA_SetPeriphIncMode(DMA1, LL_DMA_STREAM_6, LL_DMA_PERIPH_NOINCREMENT);

  LL_DMA_SetMemoryIncMode(DMA1, LL_DMA_STREAM_6, LL_DMA_MEMORY_INCREMENT);

  LL_DMA_SetPeriphSize(DMA1, LL_DMA_STREAM_6, LL_DMA_PDATAALIGN_BYTE);

  LL_DMA_SetMemorySize(DMA1, LL_DMA_STREAM_6, LL_DMA_MDATAALIGN_BYTE);

  LL_DMA_EnableFifoMode(DMA1, LL_DMA_STREAM_6);

  LL_DMA_SetFIFOThreshold(DMA1, LL_DMA_STREAM_6, LL_DMA_FIFOTHRESHOLD_FULL);

  LL_DMA_SetMemoryBurstxfer(DMA1, LL_DMA_STREAM_6, LL_DMA_MBURST_SINGLE);

  LL_DMA_SetPeriphBurstxfer(DMA1, LL_DMA_STREAM_6, LL_DMA_PBURST_SINGLE);

  /* UART4_TX Init */
  LL_DMA_SetPeriphRequest(DMA1, LL_DMA_STREAM_7, LL_DMAMUX1_REQ_UART4_TX);

  LL_DMA_SetDataTransferDirection(DMA1, LL_DMA_STREAM_7, LL_DMA_DIRECTION_MEMORY_TO_PERIPH);

  LL_DMA_SetStreamPriorityLevel(DMA1, LL_DMA_STREAM_7, LL_DMA_PRIORITY_LOW);

  LL_DMA_SetMode(DMA1, LL_DMA_STREAM_7, LL_DMA_MODE_NORMAL);

  LL_DMA_SetPeriphIncMode(DMA1, LL_DMA_STREAM_7, LL_DMA_PERIPH_NOINCREMENT);

  LL_DMA_SetMemoryIncMode(DMA1, LL_DMA_STREAM_7, LL_DMA_MEMORY_INCREMENT);

  LL_DMA_SetPeriphSize(DMA1, LL_DMA_STREAM_7, LL_DMA_PDATAALIGN_BYTE);

  LL_DMA_SetMemorySize(DMA1, LL_DMA_STREAM_7, LL_DMA_MDATAALIGN_BYTE);

  LL_DMA_EnableFifoMode(DMA1, LL_DMA_STREAM_7);

  LL_DMA_SetFIFOThreshold(DMA1, LL_DMA_STREAM_7, LL_DMA_FIFOTHRESHOLD_FULL);

  LL_DMA_SetMemoryBurstxfer(DMA1, LL_DMA_STREAM_7, LL_DMA_MBURST_SINGLE);

  LL_DMA_SetPeriphBurstxfer(DMA1, LL_DMA_STREAM_7, LL_DMA_PBURST_SINGLE);

  /* UART4 interrupt Init */
  NVIC_SetPriority(UART4_IRQn, NVIC_EncodePriority(NVIC_GetPriorityGrouping(),5, 0));
  NVIC_EnableIRQ(UART4_IRQn);

  UART_InitStruct.PrescalerValue = LL_USART_PRESCALER_DIV1;
  UART_InitStruct.BaudRate = 115200;
  UART_InitStruct.DataWidth = LL_USART_DATAWIDTH_8B;
  UART_InitStruct.StopBits = LL_USART_STOPBITS_1;
  UART_InitStruct.Parity = LL_USART_PARITY_NONE;
  UART_InitStruct.TransferDirection = LL_USART_DIRECTION_TX_RX;
  UART_InitStruct.HardwareFlowControl = LL_USART_HWCONTROL_NONE;
  UART_InitStruct.OverSampling = LL_USART_OVERSAMPLING_16;
  LL_USART_Init(UART4, &UART_InitStruct);
  LL_USART_EnableFIFO(UART4);
  LL_USART_SetTXFIFOThreshold(UART4, LL_USART_FIFOTHRESHOLD_1_8);
  LL_USART_SetRXFIFOThreshold(UART4, LL_USART_FIFOTHRESHOLD_1_8);
  LL_USART_ConfigAsyncMode(UART4);

  LL_USART_Enable(UART4);

  /* Polling UART4 initialisation */
  while((!(LL_USART_IsActiveFlag_TEACK(UART4))) || (!(LL_USART_IsActiveFlag_REACK(UART4))))
  {
  }

}

static void MX_USART1_UART_Init(void)
{

  LL_USART_InitTypeDef USART_InitStruct = {0};

  LL_GPIO_InitTypeDef GPIO_InitStruct = {0};

  LL_RCC_SetUSARTClockSource(LL_RCC_USART16_CLKSOURCE_PCLK2);

  /* Peripheral clock enable */
  LL_APB2_GRP1_EnableClock(LL_APB2_GRP1_PERIPH_USART1);

  LL_AHB4_GRP1_EnableClock(LL_AHB4_GRP1_PERIPH_GPIOA);
  /**USART1 GPIO Configuration
  PA9   ------> USART1_TX
  PA10   ------> USART1_RX
  */
  GPIO_InitStruct.Pin = TX_DEBUG_Pin|RX_DEBUG_Pin;
  GPIO_InitStruct.Mode = LL_GPIO_MODE_ALTERNATE;
  GPIO_InitStruct.Speed = LL_GPIO_SPEED_FREQ_VERY_HIGH;
  GPIO_InitStruct.OutputType = LL_GPIO_OUTPUT_PUSHPULL;
  GPIO_InitStruct.Pull = LL_GPIO_PULL_NO;
  GPIO_InitStruct.Alternate = LL_GPIO_AF_7;
  LL_GPIO_Init(GPIOA, &GPIO_InitStruct);

  /* USART1 DMA Init */

  /* USART1_RX Init */
  LL_DMA_SetPeriphRequest(DMA1, LL_DMA_STREAM_0, LL_DMAMUX1_REQ_USART1_RX);

  LL_DMA_SetDataTransferDirection(DMA1, LL_DMA_STREAM_0, LL_DMA_DIRECTION_PERIPH_TO_MEMORY);

  LL_DMA_SetStreamPriorityLevel(DMA1, LL_DMA_STREAM_0, LL_DMA_PRIORITY_LOW);

  LL_DMA_SetMode(DMA1, LL_DMA_STREAM_0, LL_DMA_MODE_NORMAL);

  LL_DMA_SetPeriphIncMode(DMA1, LL_DMA_STREAM_0, LL_DMA_PERIPH_NOINCREMENT);

  LL_DMA_SetMemoryIncMode(DMA1, LL_DMA_STREAM_0, LL_DMA_MEMORY_INCREMENT);

  LL_DMA_SetPeriphSize(DMA1, LL_DMA_STREAM_0, LL_DMA_PDATAALIGN_BYTE);

  LL_DMA_SetMemorySize(DMA1, LL_DMA_STREAM_0, LL_DMA_MDATAALIGN_BYTE);

  LL_DMA_EnableFifoMode(DMA1, LL_DMA_STREAM_0);

  LL_DMA_SetFIFOThreshold(DMA1, LL_DMA_STREAM_0, LL_DMA_FIFOTHRESHOLD_FULL);

  LL_DMA_SetMemoryBurstxfer(DMA1, LL_DMA_STREAM_0, LL_DMA_MBURST_SINGLE);

  LL_DMA_SetPeriphBurstxfer(DMA1, LL_DMA_STREAM_0, LL_DMA_PBURST_SINGLE);

  /* USART1_TX Init */
  LL_DMA_SetPeriphRequest(DMA1, LL_DMA_STREAM_1, LL_DMAMUX1_REQ_USART1_TX);

  LL_DMA_SetDataTransferDirection(DMA1, LL_DMA_STREAM_1, LL_DMA_DIRECTION_MEMORY_TO_PERIPH);

  LL_DMA_SetStreamPriorityLevel(DMA1, LL_DMA_STREAM_1, LL_DMA_PRIORITY_LOW);

  LL_DMA_SetMode(DMA1, LL_DMA_STREAM_1, LL_DMA_MODE_NORMAL);

  LL_DMA_SetPeriphIncMode(DMA1, LL_DMA_STREAM_1, LL_DMA_PERIPH_NOINCREMENT);

  LL_DMA_SetMemoryIncMode(DMA1, LL_DMA_STREAM_1, LL_DMA_MEMORY_INCREMENT);

  LL_DMA_SetPeriphSize(DMA1, LL_DMA_STREAM_1, LL_DMA_PDATAALIGN_BYTE);

  LL_DMA_SetMemorySize(DMA1, LL_DMA_STREAM_1, LL_DMA_MDATAALIGN_BYTE);

  LL_DMA_EnableFifoMode(DMA1, LL_DMA_STREAM_1);

  LL_DMA_SetFIFOThreshold(DMA1, LL_DMA_STREAM_1, LL_DMA_FIFOTHRESHOLD_FULL);

  LL_DMA_SetMemoryBurstxfer(DMA1, LL_DMA_STREAM_1, LL_DMA_MBURST_SINGLE);

  LL_DMA_SetPeriphBurstxfer(DMA1, LL_DMA_STREAM_1, LL_DMA_PBURST_SINGLE);

  /* USART1 interrupt Init */
  NVIC_SetPriority(USART1_IRQn, NVIC_EncodePriority(NVIC_GetPriorityGrouping(),5, 0));
  NVIC_EnableIRQ(USART1_IRQn);

  USART_InitStruct.PrescalerValue = LL_USART_PRESCALER_DIV1;
  USART_InitStruct.BaudRate = 1500000;
  USART_InitStruct.DataWidth = LL_USART_DATAWIDTH_8B;
  USART_InitStruct.StopBits = LL_USART_STOPBITS_1;
  USART_InitStruct.Parity = LL_USART_PARITY_NONE;
  USART_InitStruct.TransferDirection = LL_USART_DIRECTION_TX_RX;
  USART_InitStruct.HardwareFlowControl = LL_USART_HWCONTROL_NONE;
  USART_InitStruct.OverSampling = LL_USART_OVERSAMPLING_16;
  LL_USART_Init(USART1, &USART_InitStruct);
  LL_USART_SetTXFIFOThreshold(USART1, LL_USART_FIFOTHRESHOLD_1_8);
  LL_USART_SetRXFIFOThreshold(USART1, LL_USART_FIFOTHRESHOLD_1_8);
  LL_USART_EnableFIFO(USART1);
  LL_USART_ConfigAsyncMode(USART1);

  LL_USART_Enable(USART1);

  /* Polling USART1 initialisation */
  while((!(LL_USART_IsActiveFlag_TEACK(USART1))) || (!(LL_USART_IsActiveFlag_REACK(USART1))))
  {
  }
  /* USER CODE BEGIN USART1_Init 2 */
  uart1_cb.huart = USART1;
  uart1_cb.dma_rx = DMA1;
  uart1_cb.dma_tx = DMA1;
  uart1_cb.dma_rx_channel = LL_DMA_STREAM_0;
  uart1_cb.dma_tx_channel = LL_DMA_STREAM_1;
  uart1_cb.expect_dma_rx_len = 0;
  uart1_cb.expect_dma_tx_len = 0;
  uart1_cb.tx_cplt_flag = 1;

  // ring buffer initialization
  memset(uart1_cb.rx_buf, 0, sizeof(uart1_cb.rx_buf));
  memset(uart1_cb.tx_buf, 0, sizeof(uart1_cb.tx_buf));
  ringbuf_ret_t err;
  err = ringbuf_init(&uart1_cb.rx_ringbuf, uart1_cb.rx_buf, sizeof(uart1_cb.rx_buf), RINGBUF_RULE_DISCARD);
  if(err != RINGBUF_OK)
  {
    char error_str[] = "USART1 RX ringbuf init failed\n";
    for(char* p=error_str; *p!='\0'; p++)
    {
      LL_USART_TransmitData8(USART1, *p);
    }
  }
  err = ringbuf_init(&uart1_cb.tx_ringbuf, uart1_cb.tx_buf, sizeof(uart1_cb.tx_buf), RINGBUF_RULE_DISCARD);
  if(err != RINGBUF_OK)
  {
    char error_str[] = "USART1 RX ringbuf init failed\n";
    for(char* p=error_str; *p!='\0'; p++)
    {
        LL_USART_TransmitData8(USART1, *p);
    }
  }
  /* USER CODE END USART1_Init 2 */

}

static void MX_USART2_UART_Init(void)
{

  LL_USART_InitTypeDef USART_InitStruct = {0};

  LL_GPIO_InitTypeDef GPIO_InitStruct = {0};

  LL_RCC_SetUSARTClockSource(LL_RCC_USART234578_CLKSOURCE_PCLK1);

  /* Peripheral clock enable */
  LL_APB1_GRP1_EnableClock(LL_APB1_GRP1_PERIPH_USART2);

  LL_AHB4_GRP1_EnableClock(LL_AHB4_GRP1_PERIPH_GPIOD);
  /**USART2 GPIO Configuration
  PD5   ------> USART2_TX
  PD6   ------> USART2_RX
  */
  GPIO_InitStruct.Pin = TX_BLE_Pin|RX_BLE_Pin;
  GPIO_InitStruct.Mode = LL_GPIO_MODE_ALTERNATE;
  GPIO_InitStruct.Speed = LL_GPIO_SPEED_FREQ_VERY_HIGH;
  GPIO_InitStruct.OutputType = LL_GPIO_OUTPUT_PUSHPULL;
  GPIO_InitStruct.Pull = LL_GPIO_PULL_NO;
  GPIO_InitStruct.Alternate = LL_GPIO_AF_7;
  LL_GPIO_Init(GPIOD, &GPIO_InitStruct);

  /* USART2 DMA Init */

  /* USART2_RX Init */
  LL_DMA_SetPeriphRequest(DMA1, LL_DMA_STREAM_2, LL_DMAMUX1_REQ_USART2_RX);

  LL_DMA_SetDataTransferDirection(DMA1, LL_DMA_STREAM_2, LL_DMA_DIRECTION_PERIPH_TO_MEMORY);

  LL_DMA_SetStreamPriorityLevel(DMA1, LL_DMA_STREAM_2, LL_DMA_PRIORITY_LOW);

  LL_DMA_SetMode(DMA1, LL_DMA_STREAM_2, LL_DMA_MODE_NORMAL);

  LL_DMA_SetPeriphIncMode(DMA1, LL_DMA_STREAM_2, LL_DMA_PERIPH_NOINCREMENT);

  LL_DMA_SetMemoryIncMode(DMA1, LL_DMA_STREAM_2, LL_DMA_MEMORY_INCREMENT);

  LL_DMA_SetPeriphSize(DMA1, LL_DMA_STREAM_2, LL_DMA_PDATAALIGN_BYTE);

  LL_DMA_SetMemorySize(DMA1, LL_DMA_STREAM_2, LL_DMA_MDATAALIGN_BYTE);

  LL_DMA_EnableFifoMode(DMA1, LL_DMA_STREAM_2);

  LL_DMA_SetFIFOThreshold(DMA1, LL_DMA_STREAM_2, LL_DMA_FIFOTHRESHOLD_FULL);

  LL_DMA_SetMemoryBurstxfer(DMA1, LL_DMA_STREAM_2, LL_DMA_MBURST_SINGLE);

  LL_DMA_SetPeriphBurstxfer(DMA1, LL_DMA_STREAM_2, LL_DMA_PBURST_SINGLE);

  /* USART2_TX Init */
  LL_DMA_SetPeriphRequest(DMA1, LL_DMA_STREAM_3, LL_DMAMUX1_REQ_USART2_TX);

  LL_DMA_SetDataTransferDirection(DMA1, LL_DMA_STREAM_3, LL_DMA_DIRECTION_MEMORY_TO_PERIPH);

  LL_DMA_SetStreamPriorityLevel(DMA1, LL_DMA_STREAM_3, LL_DMA_PRIORITY_LOW);

  LL_DMA_SetMode(DMA1, LL_DMA_STREAM_3, LL_DMA_MODE_NORMAL);

  LL_DMA_SetPeriphIncMode(DMA1, LL_DMA_STREAM_3, LL_DMA_PERIPH_NOINCREMENT);

  LL_DMA_SetMemoryIncMode(DMA1, LL_DMA_STREAM_3, LL_DMA_MEMORY_INCREMENT);

  LL_DMA_SetPeriphSize(DMA1, LL_DMA_STREAM_3, LL_DMA_PDATAALIGN_BYTE);

  LL_DMA_SetMemorySize(DMA1, LL_DMA_STREAM_3, LL_DMA_MDATAALIGN_BYTE);

  LL_DMA_EnableFifoMode(DMA1, LL_DMA_STREAM_3);

  LL_DMA_SetFIFOThreshold(DMA1, LL_DMA_STREAM_3, LL_DMA_FIFOTHRESHOLD_FULL);

  LL_DMA_SetMemoryBurstxfer(DMA1, LL_DMA_STREAM_3, LL_DMA_MBURST_SINGLE);

  LL_DMA_SetPeriphBurstxfer(DMA1, LL_DMA_STREAM_3, LL_DMA_PBURST_SINGLE);

  /* USART2 interrupt Init */
  NVIC_SetPriority(USART2_IRQn, NVIC_EncodePriority(NVIC_GetPriorityGrouping(),5, 0));
  NVIC_EnableIRQ(USART2_IRQn);

  USART_InitStruct.PrescalerValue = LL_USART_PRESCALER_DIV1;
  USART_InitStruct.BaudRate = 115200;
  USART_InitStruct.DataWidth = LL_USART_DATAWIDTH_8B;
  USART_InitStruct.StopBits = LL_USART_STOPBITS_1;
  USART_InitStruct.Parity = LL_USART_PARITY_NONE;
  USART_InitStruct.TransferDirection = LL_USART_DIRECTION_TX_RX;
  USART_InitStruct.HardwareFlowControl = LL_USART_HWCONTROL_NONE;
  USART_InitStruct.OverSampling = LL_USART_OVERSAMPLING_16;
  LL_USART_Init(USART2, &USART_InitStruct);
  LL_USART_SetTXFIFOThreshold(USART2, LL_USART_FIFOTHRESHOLD_1_8);
  LL_USART_SetRXFIFOThreshold(USART2, LL_USART_FIFOTHRESHOLD_1_8);
  LL_USART_EnableFIFO(USART2);
  LL_USART_ConfigAsyncMode(USART2);

  LL_USART_Enable(USART2);

  /* Polling USART2 initialisation */
  while((!(LL_USART_IsActiveFlag_TEACK(USART2))) || (!(LL_USART_IsActiveFlag_REACK(USART2))))
  {
  }
  /* USER CODE BEGIN USART2_Init 2 */
  uart2_cb.huart = USART2;
  uart2_cb.dma_rx = DMA1;
  uart2_cb.dma_tx = DMA1;
  uart2_cb.dma_rx_channel = LL_DMA_STREAM_2;
  uart2_cb.dma_tx_channel = LL_DMA_STREAM_3;
  uart2_cb.expect_dma_rx_len = 0;
  uart2_cb.expect_dma_tx_len = 0;
  uart2_cb.tx_cplt_flag = 1;

  // ring buffer initialization
  memset(uart2_cb.rx_buf, 0, sizeof(uart2_cb.rx_buf));
  memset(uart2_cb.tx_buf, 0, sizeof(uart2_cb.tx_buf));
  ringbuf_ret_t err;
  err = ringbuf_init(&uart2_cb.rx_ringbuf, uart2_cb.rx_buf, sizeof(uart2_cb.rx_buf), RINGBUF_RULE_DISCARD);
  if(err != RINGBUF_OK)
  {
      // for(;;){}
      LOG_ERROR("USART2 RX ringbuf init failed");
  }
  err = ringbuf_init(&uart2_cb.tx_ringbuf, uart2_cb.tx_buf, sizeof(uart2_cb.tx_buf), RINGBUF_RULE_DISCARD);
  if(err != RINGBUF_OK)
  {
      // for(;;){}
      LOG_ERROR("USART2 TX ringbuf init failed");
  }
  /* USER CODE END USART2_Init 2 */

}

static void MX_USART3_UART_Init(void)
{

  LL_USART_InitTypeDef USART_InitStruct = {0};

  LL_GPIO_InitTypeDef GPIO_InitStruct = {0};

  LL_RCC_SetUSARTClockSource(LL_RCC_USART234578_CLKSOURCE_PCLK1);

  /* Peripheral clock enable */
  LL_APB1_GRP1_EnableClock(LL_APB1_GRP1_PERIPH_USART3);

  LL_AHB4_GRP1_EnableClock(LL_AHB4_GRP1_PERIPH_GPIOD);
  /**USART3 GPIO Configuration
  PD9   ------> USART3_RX
  PD8   ------> USART3_TX
  */
  GPIO_InitStruct.Pin = SBUS_RX_Pin|SBUS_TX_Pin;
  GPIO_InitStruct.Mode = LL_GPIO_MODE_ALTERNATE;
  GPIO_InitStruct.Speed = LL_GPIO_SPEED_FREQ_VERY_HIGH;
  GPIO_InitStruct.OutputType = LL_GPIO_OUTPUT_PUSHPULL;
  GPIO_InitStruct.Pull = LL_GPIO_PULL_NO;
  GPIO_InitStruct.Alternate = LL_GPIO_AF_7;
  LL_GPIO_Init(GPIOD, &GPIO_InitStruct);

  /* USART3 DMA Init */

  /* USART3_RX Init */
  LL_DMA_SetPeriphRequest(DMA1, LL_DMA_STREAM_4, LL_DMAMUX1_REQ_USART3_RX);

  LL_DMA_SetDataTransferDirection(DMA1, LL_DMA_STREAM_4, LL_DMA_DIRECTION_PERIPH_TO_MEMORY);

  LL_DMA_SetStreamPriorityLevel(DMA1, LL_DMA_STREAM_4, LL_DMA_PRIORITY_LOW);

  LL_DMA_SetMode(DMA1, LL_DMA_STREAM_4, LL_DMA_MODE_NORMAL);

  LL_DMA_SetPeriphIncMode(DMA1, LL_DMA_STREAM_4, LL_DMA_PERIPH_NOINCREMENT);

  LL_DMA_SetMemoryIncMode(DMA1, LL_DMA_STREAM_4, LL_DMA_MEMORY_INCREMENT);

  LL_DMA_SetPeriphSize(DMA1, LL_DMA_STREAM_4, LL_DMA_PDATAALIGN_BYTE);

  LL_DMA_SetMemorySize(DMA1, LL_DMA_STREAM_4, LL_DMA_MDATAALIGN_BYTE);

  LL_DMA_DisableFifoMode(DMA1, LL_DMA_STREAM_4);

  /* USART3_TX Init */
  LL_DMA_SetPeriphRequest(DMA1, LL_DMA_STREAM_5, LL_DMAMUX1_REQ_USART3_TX);

  LL_DMA_SetDataTransferDirection(DMA1, LL_DMA_STREAM_5, LL_DMA_DIRECTION_MEMORY_TO_PERIPH);

  LL_DMA_SetStreamPriorityLevel(DMA1, LL_DMA_STREAM_5, LL_DMA_PRIORITY_LOW);

  LL_DMA_SetMode(DMA1, LL_DMA_STREAM_5, LL_DMA_MODE_NORMAL);

  LL_DMA_SetPeriphIncMode(DMA1, LL_DMA_STREAM_5, LL_DMA_PERIPH_NOINCREMENT);

  LL_DMA_SetMemoryIncMode(DMA1, LL_DMA_STREAM_5, LL_DMA_MEMORY_INCREMENT);

  LL_DMA_SetPeriphSize(DMA1, LL_DMA_STREAM_5, LL_DMA_PDATAALIGN_BYTE);

  LL_DMA_SetMemorySize(DMA1, LL_DMA_STREAM_5, LL_DMA_MDATAALIGN_BYTE);

  LL_DMA_DisableFifoMode(DMA1, LL_DMA_STREAM_5);

  /* USART3 interrupt Init */
  NVIC_SetPriority(USART3_IRQn, NVIC_EncodePriority(NVIC_GetPriorityGrouping(),5, 0));
  NVIC_EnableIRQ(USART3_IRQn);

  USART_InitStruct.PrescalerValue = LL_USART_PRESCALER_DIV1;
  USART_InitStruct.BaudRate = 115200;
  USART_InitStruct.DataWidth = LL_USART_DATAWIDTH_8B;
  USART_InitStruct.StopBits = LL_USART_STOPBITS_1;
  USART_InitStruct.Parity = LL_USART_PARITY_NONE;
  USART_InitStruct.TransferDirection = LL_USART_DIRECTION_TX_RX;
  USART_InitStruct.HardwareFlowControl = LL_USART_HWCONTROL_NONE;
  USART_InitStruct.OverSampling = LL_USART_OVERSAMPLING_16;
  LL_USART_Init(USART3, &USART_InitStruct);
  LL_USART_SetTXFIFOThreshold(USART3, LL_USART_FIFOTHRESHOLD_1_8);
  LL_USART_SetRXFIFOThreshold(USART3, LL_USART_FIFOTHRESHOLD_1_8);
  LL_USART_EnableFIFO(USART3);
  LL_USART_ConfigAsyncMode(USART3);

  LL_USART_Enable(USART3);

  /* Polling USART3 initialisation */
  while((!(LL_USART_IsActiveFlag_TEACK(USART3))) || (!(LL_USART_IsActiveFlag_REACK(USART3))))
  {
  }
  /* USER CODE BEGIN USART3_Init 2 */
  uart3_cb.huart = USART3;
  uart3_cb.dma_rx = DMA1;
  uart3_cb.dma_tx = DMA1;
  uart3_cb.dma_rx_channel = LL_DMA_STREAM_4;
  uart3_cb.dma_tx_channel = LL_DMA_STREAM_5;
  uart3_cb.expect_dma_rx_len = 0;
  uart3_cb.expect_dma_tx_len = 0;
  uart3_cb.tx_cplt_flag = 1;

  // ring buffer initialization
  memset(uart3_cb.rx_buf, 0, sizeof(uart3_cb.rx_buf));
  memset(uart3_cb.tx_buf, 0, sizeof(uart3_cb.tx_buf));
  ringbuf_ret_t err;
  err = ringbuf_init(&uart3_cb.rx_ringbuf, uart3_cb.rx_buf, sizeof(uart3_cb.rx_buf), RINGBUF_RULE_DISCARD);
  if(err != RINGBUF_OK)
  {
      // for(;;){}
      LOG_ERROR("USART3 RX ringbuf init failed");
  }
  err = ringbuf_init(&uart3_cb.tx_ringbuf, uart3_cb.tx_buf, sizeof(uart3_cb.tx_buf), RINGBUF_RULE_DISCARD);
  if(err != RINGBUF_OK)
  {
      // for(;;){}
      LOG_ERROR("USART3 TX ringbuf init failed");
  }
  /* USER CODE END USART3_Init 2 */

}

static void MX_DMA_Init(void)
{

  /* Init with LL driver */
  /* DMA controller clock enable */
  LL_AHB1_GRP1_EnableClock(LL_AHB1_GRP1_PERIPH_DMA1);
  LL_AHB1_GRP1_EnableClock(LL_AHB1_GRP1_PERIPH_DMA2);

  /* DMA interrupt init */
  /* DMA1_Stream0_IRQn interrupt configuration */
  NVIC_SetPriority(DMA1_Stream0_IRQn, NVIC_EncodePriority(NVIC_GetPriorityGrouping(),5, 0));
  NVIC_EnableIRQ(DMA1_Stream0_IRQn);
  /* DMA1_Stream1_IRQn interrupt configuration */
  NVIC_SetPriority(DMA1_Stream1_IRQn, NVIC_EncodePriority(NVIC_GetPriorityGrouping(),5, 0));
  NVIC_EnableIRQ(DMA1_Stream1_IRQn);
  /* DMA1_Stream2_IRQn interrupt configuration */
  NVIC_SetPriority(DMA1_Stream2_IRQn, NVIC_EncodePriority(NVIC_GetPriorityGrouping(),5, 0));
  NVIC_EnableIRQ(DMA1_Stream2_IRQn);
  /* DMA1_Stream3_IRQn interrupt configuration */
  NVIC_SetPriority(DMA1_Stream3_IRQn, NVIC_EncodePriority(NVIC_GetPriorityGrouping(),5, 0));
  NVIC_EnableIRQ(DMA1_Stream3_IRQn);
  /* DMA1_Stream4_IRQn interrupt configuration */
  NVIC_SetPriority(DMA1_Stream4_IRQn, NVIC_EncodePriority(NVIC_GetPriorityGrouping(),5, 0));
  NVIC_EnableIRQ(DMA1_Stream4_IRQn);
  /* DMA1_Stream5_IRQn interrupt configuration */
  NVIC_SetPriority(DMA1_Stream5_IRQn, NVIC_EncodePriority(NVIC_GetPriorityGrouping(),5, 0));
  NVIC_EnableIRQ(DMA1_Stream5_IRQn);
  /* DMA1_Stream6_IRQn interrupt configuration */
  NVIC_SetPriority(DMA1_Stream6_IRQn, NVIC_EncodePriority(NVIC_GetPriorityGrouping(),5, 0));
  NVIC_EnableIRQ(DMA1_Stream6_IRQn);
  /* DMA1_Stream7_IRQn interrupt configuration */
  NVIC_SetPriority(DMA1_Stream7_IRQn, NVIC_EncodePriority(NVIC_GetPriorityGrouping(),5, 0));
  NVIC_EnableIRQ(DMA1_Stream7_IRQn);
  /* DMA2_Stream0_IRQn interrupt configuration */
  NVIC_SetPriority(DMA2_Stream0_IRQn, NVIC_EncodePriority(NVIC_GetPriorityGrouping(),5, 0));
  NVIC_EnableIRQ(DMA2_Stream0_IRQn);
  /* DMA2_Stream1_IRQn interrupt configuration */
  NVIC_SetPriority(DMA2_Stream1_IRQn, NVIC_EncodePriority(NVIC_GetPriorityGrouping(),5, 0));
  NVIC_EnableIRQ(DMA2_Stream1_IRQn);
  /* DMA2_Stream2_IRQn interrupt configuration */
  NVIC_SetPriority(DMA2_Stream2_IRQn, NVIC_EncodePriority(NVIC_GetPriorityGrouping(),5, 0));
  NVIC_EnableIRQ(DMA2_Stream2_IRQn);
  /* DMA2_Stream4_IRQn interrupt configuration */
  NVIC_SetPriority(DMA2_Stream4_IRQn, NVIC_EncodePriority(NVIC_GetPriorityGrouping(),5, 0));
  NVIC_EnableIRQ(DMA2_Stream4_IRQn);

}

static void MX_GPIO_Init(void)
{
  LL_EXTI_InitTypeDef EXTI_InitStruct = {0};
  LL_GPIO_InitTypeDef GPIO_InitStruct = {0};

  /* GPIO Ports Clock Enable */
  LL_AHB4_GRP1_EnableClock(LL_AHB4_GRP1_PERIPH_GPIOC);
  LL_AHB4_GRP1_EnableClock(LL_AHB4_GRP1_PERIPH_GPIOE);
  LL_AHB4_GRP1_EnableClock(LL_AHB4_GRP1_PERIPH_GPIOB);
  LL_AHB4_GRP1_EnableClock(LL_AHB4_GRP1_PERIPH_GPIOA);
  LL_AHB4_GRP1_EnableClock(LL_AHB4_GRP1_PERIPH_GPIOD);
  LL_AHB4_GRP1_EnableClock(LL_AHB4_GRP1_PERIPH_GPIOH);

  /**/
  LL_GPIO_SetOutputPin(SPI_CS_EXT_GPIO_Port, SPI_CS_EXT_Pin);

  /**/
  LL_GPIO_SetOutputPin(OLED_RESET_GPIO_Port, OLED_RESET_Pin);

  /**/
  LL_GPIO_SetOutputPin(SPI_CS_OLED_GPIO_Port, SPI_CS_OLED_Pin);

  /**/
  LL_GPIO_SetOutputPin(ETH_RESET_GPIO_Port, ETH_RESET_Pin);

  /**/
  LL_GPIO_ResetOutputPin(OLED_DC_GPIO_Port, OLED_DC_Pin);

  /**/
  LL_GPIO_ResetOutputPin(GPIOE, CTRL_MOTOR4_Pin|CTRL_MOTOR3_Pin|FAULT_MOTOR4_Pin|CTRL_MOTOR1_Pin
                          |CTRL_MOTOR2_Pin);

  /**/
  GPIO_InitStruct.Pin = SPI_CS_EXT_Pin;
  GPIO_InitStruct.Mode = LL_GPIO_MODE_OUTPUT;
  GPIO_InitStruct.Speed = LL_GPIO_SPEED_FREQ_LOW;
  GPIO_InitStruct.OutputType = LL_GPIO_OUTPUT_PUSHPULL;
  GPIO_InitStruct.Pull = LL_GPIO_PULL_NO;
  LL_GPIO_Init(SPI_CS_EXT_GPIO_Port, &GPIO_InitStruct);

  /**/
  GPIO_InitStruct.Pin = LL_GPIO_PIN_2;
  GPIO_InitStruct.Mode = LL_GPIO_MODE_ANALOG;
  GPIO_InitStruct.Pull = LL_GPIO_PULL_NO;
  LL_GPIO_Init(GPIOE, &GPIO_InitStruct);

  /**/
  GPIO_InitStruct.Pin = OLED_RESET_Pin|OLED_DC_Pin;
  GPIO_InitStruct.Mode = LL_GPIO_MODE_OUTPUT;
  GPIO_InitStruct.Speed = LL_GPIO_SPEED_FREQ_LOW;
  GPIO_InitStruct.OutputType = LL_GPIO_OUTPUT_PUSHPULL;
  GPIO_InitStruct.Pull = LL_GPIO_PULL_NO;
  LL_GPIO_Init(GPIOD, &GPIO_InitStruct);

  /**/
  GPIO_InitStruct.Pin = SPI_CS_OLED_Pin;
  GPIO_InitStruct.Mode = LL_GPIO_MODE_OUTPUT;
  GPIO_InitStruct.Speed = LL_GPIO_SPEED_FREQ_LOW;
  GPIO_InitStruct.OutputType = LL_GPIO_OUTPUT_PUSHPULL;
  GPIO_InitStruct.Pull = LL_GPIO_PULL_NO;
  LL_GPIO_Init(SPI_CS_OLED_GPIO_Port, &GPIO_InitStruct);

  /**/
  GPIO_InitStruct.Pin = LL_GPIO_PIN_2;
  GPIO_InitStruct.Mode = LL_GPIO_MODE_ANALOG;
  GPIO_InitStruct.Pull = LL_GPIO_PULL_NO;
  LL_GPIO_Init(GPIOC, &GPIO_InitStruct);

  /**/
  GPIO_InitStruct.Pin = ETH_RESET_Pin|CTRL_MOTOR4_Pin|CTRL_MOTOR3_Pin|FAULT_MOTOR4_Pin
                          |CTRL_MOTOR1_Pin|CTRL_MOTOR2_Pin;
  GPIO_InitStruct.Mode = LL_GPIO_MODE_OUTPUT;
  GPIO_InitStruct.Speed = LL_GPIO_SPEED_FREQ_LOW;
  GPIO_InitStruct.OutputType = LL_GPIO_OUTPUT_PUSHPULL;
  GPIO_InitStruct.Pull = LL_GPIO_PULL_NO;
  LL_GPIO_Init(GPIOE, &GPIO_InitStruct);

  /**/
  LL_SYSCFG_SetEXTISource(LL_SYSCFG_EXTI_PORTC, LL_SYSCFG_EXTI_LINE15);

  /**/
  LL_SYSCFG_SetEXTISource(LL_SYSCFG_EXTI_PORTE, LL_SYSCFG_EXTI_LINE3);

  /**/
  LL_SYSCFG_SetEXTISource(LL_SYSCFG_EXTI_PORTE, LL_SYSCFG_EXTI_LINE4);

  /**/
  LL_SYSCFG_SetEXTISource(LL_SYSCFG_EXTI_PORTE, LL_SYSCFG_EXTI_LINE0);

  /**/
  LL_SYSCFG_SetEXTISource(LL_SYSCFG_EXTI_PORTB, LL_SYSCFG_EXTI_LINE2);

  /**/
  LL_SYSCFG_SetEXTISource(LL_SYSCFG_EXTI_PORTD, LL_SYSCFG_EXTI_LINE10);

  /**/
  LL_SYSCFG_SetEXTISource(LL_SYSCFG_EXTI_PORTE, LL_SYSCFG_EXTI_LINE12);

  /**/
  EXTI_InitStruct.Line_0_31 = LL_EXTI_LINE_15;
  EXTI_InitStruct.Line_32_63 = LL_EXTI_LINE_NONE;
  EXTI_InitStruct.Line_64_95 = LL_EXTI_LINE_NONE;
  EXTI_InitStruct.LineCommand = ENABLE;
  EXTI_InitStruct.Mode = LL_EXTI_MODE_IT;
  EXTI_InitStruct.Trigger = LL_EXTI_TRIGGER_RISING;
  LL_EXTI_Init(&EXTI_InitStruct);

  /**/
  EXTI_InitStruct.Line_0_31 = LL_EXTI_LINE_3;
  EXTI_InitStruct.Line_32_63 = LL_EXTI_LINE_NONE;
  EXTI_InitStruct.Line_64_95 = LL_EXTI_LINE_NONE;
  EXTI_InitStruct.LineCommand = ENABLE;
  EXTI_InitStruct.Mode = LL_EXTI_MODE_IT;
  EXTI_InitStruct.Trigger = LL_EXTI_TRIGGER_RISING;
  LL_EXTI_Init(&EXTI_InitStruct);

  /**/
  EXTI_InitStruct.Line_0_31 = LL_EXTI_LINE_4;
  EXTI_InitStruct.Line_32_63 = LL_EXTI_LINE_NONE;
  EXTI_InitStruct.Line_64_95 = LL_EXTI_LINE_NONE;
  EXTI_InitStruct.LineCommand = ENABLE;
  EXTI_InitStruct.Mode = LL_EXTI_MODE_IT;
  EXTI_InitStruct.Trigger = LL_EXTI_TRIGGER_RISING;
  LL_EXTI_Init(&EXTI_InitStruct);

  /**/
  EXTI_InitStruct.Line_0_31 = LL_EXTI_LINE_0;
  EXTI_InitStruct.Line_32_63 = LL_EXTI_LINE_NONE;
  EXTI_InitStruct.Line_64_95 = LL_EXTI_LINE_NONE;
  EXTI_InitStruct.LineCommand = ENABLE;
  EXTI_InitStruct.Mode = LL_EXTI_MODE_IT;
  EXTI_InitStruct.Trigger = LL_EXTI_TRIGGER_RISING;
  LL_EXTI_Init(&EXTI_InitStruct);

  /**/
  EXTI_InitStruct.Line_0_31 = LL_EXTI_LINE_2;
  EXTI_InitStruct.Line_32_63 = LL_EXTI_LINE_NONE;
  EXTI_InitStruct.Line_64_95 = LL_EXTI_LINE_NONE;
  EXTI_InitStruct.LineCommand = ENABLE;
  EXTI_InitStruct.Mode = LL_EXTI_MODE_IT;
  EXTI_InitStruct.Trigger = LL_EXTI_TRIGGER_RISING;
  LL_EXTI_Init(&EXTI_InitStruct);

  /**/
  EXTI_InitStruct.Line_0_31 = LL_EXTI_LINE_10;
  EXTI_InitStruct.Line_32_63 = LL_EXTI_LINE_NONE;
  EXTI_InitStruct.Line_64_95 = LL_EXTI_LINE_NONE;
  EXTI_InitStruct.LineCommand = ENABLE;
  EXTI_InitStruct.Mode = LL_EXTI_MODE_IT;
  EXTI_InitStruct.Trigger = LL_EXTI_TRIGGER_RISING;
  LL_EXTI_Init(&EXTI_InitStruct);

  /**/
  EXTI_InitStruct.Line_0_31 = LL_EXTI_LINE_12;
  EXTI_InitStruct.Line_32_63 = LL_EXTI_LINE_NONE;
  EXTI_InitStruct.Line_64_95 = LL_EXTI_LINE_NONE;
  EXTI_InitStruct.LineCommand = ENABLE;
  EXTI_InitStruct.Mode = LL_EXTI_MODE_IT;
  EXTI_InitStruct.Trigger = LL_EXTI_TRIGGER_RISING;
  LL_EXTI_Init(&EXTI_InitStruct);

  /**/
  LL_GPIO_SetPinPull(FAULT_MOTOR1_GPIO_Port, FAULT_MOTOR1_Pin, LL_GPIO_PULL_NO);

  /**/
  LL_GPIO_SetPinPull(IMU_INT2_GPIO_Port, IMU_INT2_Pin, LL_GPIO_PULL_NO);

  /**/
  LL_GPIO_SetPinPull(EXT_RTC_INT_GPIO_Port, EXT_RTC_INT_Pin, LL_GPIO_PULL_NO);

  /**/
  LL_GPIO_SetPinPull(BUTTON_GPIO_Port, BUTTON_Pin, LL_GPIO_PULL_NO);

  /**/
  LL_GPIO_SetPinPull(FAULT_MOTOR3_GPIO_Port, FAULT_MOTOR3_Pin, LL_GPIO_PULL_NO);

  /**/
  LL_GPIO_SetPinPull(IMU_INT1_GPIO_Port, IMU_INT1_Pin, LL_GPIO_PULL_NO);

  /**/
  LL_GPIO_SetPinPull(FAULT_MOTOR2_GPIO_Port, FAULT_MOTOR2_Pin, LL_GPIO_PULL_NO);

  /**/
  LL_GPIO_SetPinMode(FAULT_MOTOR1_GPIO_Port, FAULT_MOTOR1_Pin, LL_GPIO_MODE_INPUT);

  /**/
  LL_GPIO_SetPinMode(IMU_INT2_GPIO_Port, IMU_INT2_Pin, LL_GPIO_MODE_INPUT);

  /**/
  LL_GPIO_SetPinMode(EXT_RTC_INT_GPIO_Port, EXT_RTC_INT_Pin, LL_GPIO_MODE_INPUT);

  /**/
  LL_GPIO_SetPinMode(BUTTON_GPIO_Port, BUTTON_Pin, LL_GPIO_MODE_INPUT);

  /**/
  LL_GPIO_SetPinMode(FAULT_MOTOR3_GPIO_Port, FAULT_MOTOR3_Pin, LL_GPIO_MODE_INPUT);

  /**/
  LL_GPIO_SetPinMode(IMU_INT1_GPIO_Port, IMU_INT1_Pin, LL_GPIO_MODE_INPUT);

  /**/
  LL_GPIO_SetPinMode(FAULT_MOTOR2_GPIO_Port, FAULT_MOTOR2_Pin, LL_GPIO_MODE_INPUT);

  /* EXTI interrupt init*/
  NVIC_SetPriority(EXTI0_IRQn, NVIC_EncodePriority(NVIC_GetPriorityGrouping(),5, 0));
  NVIC_EnableIRQ(EXTI0_IRQn);
  NVIC_SetPriority(EXTI2_IRQn, NVIC_EncodePriority(NVIC_GetPriorityGrouping(),5, 0));
  NVIC_EnableIRQ(EXTI2_IRQn);
  NVIC_SetPriority(EXTI3_IRQn, NVIC_EncodePriority(NVIC_GetPriorityGrouping(),5, 0));
  NVIC_EnableIRQ(EXTI3_IRQn);
  NVIC_SetPriority(EXTI4_IRQn, NVIC_EncodePriority(NVIC_GetPriorityGrouping(),5, 0));
  NVIC_EnableIRQ(EXTI4_IRQn);
  NVIC_SetPriority(EXTI15_10_IRQn, NVIC_EncodePriority(NVIC_GetPriorityGrouping(),5, 0));
  NVIC_EnableIRQ(EXTI15_10_IRQn);

}

/* USER CODE BEGIN 4 */
int uart_open(uart_t* pcb)
{
    void* p;
    size_t len;
    ringbuf_ret_t err;
    err = ringbuf_get_free_continuous_block(&pcb->rx_ringbuf, &p, &len);
    if(err != RINGBUF_OK)
    {
        return -1;
    }

    // dma receive initialization
    LL_USART_EnableDMAReq_RX(pcb->huart);
    LL_DMA_SetPeriphAddress(pcb->dma_rx, pcb->dma_rx_channel, (uint32_t)&pcb->huart->RDR);
    LL_DMA_SetMemoryAddress(pcb->dma_rx, pcb->dma_rx_channel, (uint32_t)p);
    LL_DMA_SetDataLength(pcb->dma_rx, pcb->dma_rx_channel, len);
    pcb->expect_dma_rx_len = len;
    LL_DMA_EnableIT_TC(pcb->dma_rx, pcb->dma_rx_channel);
    LL_DMA_EnableStream(pcb->dma_rx, pcb->dma_rx_channel);
    LL_USART_EnableIT_IDLE(pcb->huart);

    // dma transmission initialization
    LL_USART_EnableDMAReq_TX(pcb->huart);
    LL_DMA_SetPeriphAddress(pcb->dma_tx, pcb->dma_tx_channel, (uint32_t)&pcb->huart->TDR);
    LL_DMA_DisableIT_TC(pcb->dma_tx, pcb->dma_tx_channel);
    LL_DMA_DisableStream(pcb->dma_tx, pcb->dma_tx_channel);
    return 0;
}

int uart_close(uart_t* pcb)
{
    LL_USART_DisableDMAReq_RX(pcb->huart);
    LL_USART_DisableDMAReq_TX(pcb->huart);
    LL_DMA_DisableIT_TC(pcb->dma_rx, pcb->dma_rx_channel);
    LL_DMA_DisableStream(pcb->dma_rx, pcb->dma_rx_channel);
    LL_USART_DisableIT_IDLE(pcb->huart);
    LL_USART_DisableIT_TC(pcb->huart);
    return 0;
}

int uart_send(uart_t* pcb, void* pdata, size_t length)
{
    void* p;
    size_t len;
    ringbuf_ret_t err;
    while(pcb->tx_ringbuf.capacity - pcb->tx_ringbuf.size < length){}
    /**
     * @TODO: check whether `LL_DMA_IsEnabledStream()` can determine DMA
     * is transmitting or not.
     */
    if(LL_DMA_IsEnabledStream(pcb->dma_tx, pcb->dma_tx_channel))
    {
        /**
         * @note program will enters DMA interrupt handler as soon as
         * DMA stream is disabled and the "Transmission Complete"
         * flag will be set as well.
         */
        LL_DMA_DisableStream(pcb->dma_tx, pcb->dma_tx_channel);
    }
    err = ringbuf_write_block(&pcb->tx_ringbuf, pdata, length);
    if(err != RINGBUF_OK)
    {
        LOG_ERROR("UART send error: ringbuf error:%d\n", err);
        return -1;
    }
    err = ringbuf_get_stuffed_continuous_block(&pcb->tx_ringbuf, &p, &len);
    if(err != RINGBUF_OK)
    {
        LOG_ERROR("UART send error: ringbuf error:%d\n", err);
        return -1;
    }
    __DSB();
    SCB_CleanInvalidateDCache();
    LL_DMA_DisableStream(pcb->dma_tx, pcb->dma_tx_channel);
    LL_DMA_SetMemoryAddress(pcb->dma_tx, pcb->dma_tx_channel, (uint32_t)p);
    LL_DMA_SetDataLength(pcb->dma_tx, pcb->dma_tx_channel, (uint32_t)len);
    LL_DMA_EnableIT_TC(pcb->dma_tx, pcb->dma_tx_channel);
    pcb->expect_dma_tx_len = len;
    LL_DMA_EnableStream(pcb->dma_tx, pcb->dma_tx_channel);
    return 0;
}

int uart_read(uart_t* pcb, void* pdata, size_t length, size_t* read_length)
{
    int err = ringbuf_get_block(&pcb->rx_ringbuf, pdata, length, read_length);
    return err;
}

/**
  * @brief  This function performs one random number generation.
  *
  * @retval uint32_t unsigned 32-bit random number
  */
uint32_t get_random_number(void)
{
  uint32_t rand_num = 0;

  // LL_RNG_EnableCondReset(RNG);
  // LL_RNG_SetHealthConfig(RNG,0x17590ABCU);
  // LL_RNG_SetHealthConfig(RNG,0x00007274U);
  // LL_RNG_DisableCondReset(RNG);

  /* Initialize random numbers generation */
  LL_RNG_Enable(RNG);

  /* Generate Random 32bit Numbers */
  /* Wait for DRDY flag to be raised */
  while (!LL_RNG_IsActiveFlag_DRDY(RNG));

  /* Check if error occurs */
  if ((LL_RNG_IsActiveFlag_CECS(RNG) ) || (LL_RNG_IsActiveFlag_SECS(RNG)))
  {
    return 0;
  }

  /* Otherwise, no error detected : Value of generated random number could be retrieved
    and stored in variable */
  rand_num = LL_RNG_ReadRandData32(RNG);

  /* Stop random numbers generation */
  LL_RNG_Disable(RNG);

  return rand_num;
}

/* USER CODE END 4 */

void startup(void const * argument)
{
  /* init code for LWIP */
  MX_LWIP_Init();

  /* init code for USB_DEVICE */
  MX_USB_DEVICE_Init();
  /* USER CODE BEGIN 5 */

  buzzer_set_frequency(500);
  buzzer_on();
  vTaskDelay(pdMS_TO_TICKS(200));
  buzzer_off();

  battery_init();

  ws2812b_init();
  ws2812b_set_color(0, 255, 255, 255);
  ws2812b_set_color(1, 100, 0, 0);
  ws2812b_set_color(2, 0, 100, 0);
  ws2812b_set_color(3, 0, 0, 100);
  ws2812b_flush();
  /**
   * @note User must ensure the parameters in `drv8874_init()` are correct,
   * or the motor driver may be damaged. `torque_coefficient` and `encoder_round_count`
   * are the most important parameters for different DC motors.
   */
  drv8874_init();
  drv8874_set_position_mode(&motors[1]);
  drv8874_set_position(&motors[1], 6.28);
  // drv8874_set_velocity_mode(&motors[1]);
  // drv8874_set_velocity(&motors[1], 6.28);
  // drv8874_set_current_mode(&motors[1]);
  // drv8874_set_current(&motors[1], 0.1);
  drv8874_start(&motors[1]);

  /* Infinite loop */
  for(;;)
  {
    vTaskDelay(pdMS_TO_TICKS(1000));
    LL_IWDG_ReloadCounter(IWDG1);
  }
  /* USER CODE END 5 */
}

void cmd_process(void const * argument)
{
  /* USER CODE BEGIN cmd_process */
  /* offset of the delimeter '\n' in debug UART receipt ring buffer */
  size_t delimeter_offset = 0;

  /* FreeRTOS command line interface internal buffer */
  char* freertos_cli_write_buf = FreeRTOS_CLIGetOutputBuffer();

  /* A continuous memory buffer to process command and its parameters. */
  char command_str[64] = {0};

  for(;;)
  {
    vTaskDelay(100);
    /* Find delimeter '\n' in debug UART receipt buffer. */
    if (ringbuf_find_byte(&uart1_cb.rx_ringbuf, '\n', &delimeter_offset) != RINGBUF_OK)
    {
      /* If delimeter '\n' not found, continue processing loop. */
      continue;
    }
    /* If delimeter '\n' is found in debug UART receipt buffer,
     * move the command line string to continous memory buffer to process. */
    size_t read_len = 0;
    memset(command_str, 0, sizeof(command_str));
    if (ringbuf_get_block(&uart1_cb.rx_ringbuf, command_str, delimeter_offset + 1, &read_len) != RINGBUF_OK)
    {
      /* If failed to get command line string, continue processing loop. */
      LOG_ERROR("Failed to get command line string from UART1 ring buffer.");
      continue;
    }
    /* Process command line string. */
    if (FreeRTOS_CLIProcessCommand(command_str, freertos_cli_write_buf, configCOMMAND_INT_MAX_OUTPUT_SIZE) == pdFALSE)
    {
      /* If failed to process command line string, continue processing loop. */
      LOG_ERROR("Failed to process command line string.");
      continue;
    }
    /* Send processed command line string to debug UART transmission buffer. */
    uart_send(&uart1_cb, freertos_cli_write_buf, strlen((char*)freertos_cli_write_buf));
  }
  /* USER CODE END cmd_process */
}

 /* MPU Configuration */

void MPU_Config(void)
{

  /* Disables the MPU */
  LL_MPU_Disable();

  /** Initializes and configures the Region and the memory to be protected
  */
  LL_MPU_ConfigRegion(LL_MPU_REGION_NUMBER0, 0x87, 0x0, LL_MPU_REGION_SIZE_4GB|LL_MPU_TEX_LEVEL0|LL_MPU_REGION_NO_ACCESS|LL_MPU_INSTRUCTION_ACCESS_DISABLE|LL_MPU_ACCESS_SHAREABLE|LL_MPU_ACCESS_NOT_CACHEABLE|LL_MPU_ACCESS_NOT_BUFFERABLE);

  /** Initializes and configures the Region and the memory to be protected
  */
  LL_MPU_ConfigRegion(LL_MPU_REGION_NUMBER1, 0x0, 0x30020000, LL_MPU_REGION_SIZE_512B|LL_MPU_TEX_LEVEL0|LL_MPU_REGION_FULL_ACCESS|LL_MPU_INSTRUCTION_ACCESS_ENABLE|LL_MPU_ACCESS_NOT_SHAREABLE|LL_MPU_ACCESS_NOT_CACHEABLE|LL_MPU_ACCESS_BUFFERABLE);

  /** Initializes and configures the Region and the memory to be protected
  */
  LL_MPU_ConfigRegion(LL_MPU_REGION_NUMBER2, 0x0, 0x30000000, LL_MPU_REGION_SIZE_128KB|LL_MPU_TEX_LEVEL1|LL_MPU_REGION_FULL_ACCESS|LL_MPU_INSTRUCTION_ACCESS_DISABLE|LL_MPU_ACCESS_NOT_SHAREABLE|LL_MPU_ACCESS_NOT_CACHEABLE|LL_MPU_ACCESS_NOT_BUFFERABLE);
  /* Enables the MPU */
  LL_MPU_Enable(LL_MPU_CTRL_PRIVILEGED_DEFAULT);

}

void HAL_TIM_PeriodElapsedCallback(TIM_HandleTypeDef *htim)
{
  if (htim->Instance == TIM6)
  {
    HAL_IncTick();
  }
}

void Error_Handler(void)
{
  __disable_irq();
  while (1)
  {
  }
}

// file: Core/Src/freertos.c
/* USER CODE BEGIN Header */
/**
  ******************************************************************************
  * File Name          : freertos.c
  * Description        : Code for freertos applications
  ******************************************************************************
  * @attention
  *
  * Copyright (c) 2025 STMicroelectronics.
  * All rights reserved.
  *
  * This software is licensed under terms that can be found in the LICENSE file
  * in the root directory of this software component.
  * If no LICENSE file comes with this software, it is provided AS-IS.
  *
  ******************************************************************************
  */
/* USER CODE END Header */

#include "FreeRTOS.h"
#include "task.h"
#include "main.h"

/* USER CODE BEGIN Includes */
#include "syslog.h"
/* USER CODE END Includes */

/* GetIdleTaskMemory prototype (linked to static allocation support) */
void vApplicationGetIdleTaskMemory( StaticTask_t **ppxIdleTaskTCBBuffer, StackType_t **ppxIdleTaskStackBuffer, uint32_t *pulIdleTaskStackSize );

/* GetTimerTaskMemory prototype (linked to static allocation support) */
void vApplicationGetTimerTaskMemory( StaticTask_t **ppxTimerTaskTCBBuffer, StackType_t **ppxTimerTaskStackBuffer, uint32_t *pulTimerTaskStackSize );

/* Hook prototypes */
void configureTimerForRunTimeStats(void);
unsigned long getRunTimeCounterValue(void);
void vApplicationStackOverflowHook(xTaskHandle xTask, signed char *pcTaskName);

/* USER CODE BEGIN 1 */
/* Functions needed when configGENERATE_RUN_TIME_STATS is on */
__weak void configureTimerForRunTimeStats(void)
{

}

__weak unsigned long getRunTimeCounterValue(void)
{
return uwTick;
}
/* USER CODE END 1 */

/* USER CODE BEGIN 4 */
__weak void vApplicationStackOverflowHook(xTaskHandle xTask, signed char *pcTaskName)
{
   /* Run time stack overflow checking is performed if
   configCHECK_FOR_STACK_OVERFLOW is defined to 1 or 2. This hook function is
   called if a stack overflow is detected. */
  LOG_CRITICAL("Stack Overflow in %s\n", pcTaskName);
}
/* USER CODE END 4 */

/* USER CODE BEGIN GET_IDLE_TASK_MEMORY */
static StaticTask_t xIdleTaskTCBBuffer;
static StackType_t xIdleStack[configMINIMAL_STACK_SIZE];

void vApplicationGetIdleTaskMemory( StaticTask_t **ppxIdleTaskTCBBuffer, StackType_t **ppxIdleTaskStackBuffer, uint32_t *pulIdleTaskStackSize )
{
  *ppxIdleTaskTCBBuffer = &xIdleTaskTCBBuffer;
  *ppxIdleTaskStackBuffer = &xIdleStack[0];
  *pulIdleTaskStackSize = configMINIMAL_STACK_SIZE;
  /* place for user code */
}
/* USER CODE END GET_IDLE_TASK_MEMORY */

/* USER CODE BEGIN GET_TIMER_TASK_MEMORY */
static StaticTask_t xTimerTaskTCBBuffer;
static StackType_t xTimerStack[configTIMER_TASK_STACK_DEPTH];

void vApplicationGetTimerTaskMemory( StaticTask_t **ppxTimerTaskTCBBuffer, StackType_t **ppxTimerTaskStackBuffer, uint32_t *pulTimerTaskStackSize )
{
  *ppxTimerTaskTCBBuffer = &xTimerTaskTCBBuffer;
  *ppxTimerTaskStackBuffer = &xTimerStack[0];
  *pulTimerTaskStackSize = configTIMER_TASK_STACK_DEPTH;
  /* place for user code */
}
/* USER CODE END GET_TIMER_TASK_MEMORY */
